AUTOSAR XML (schema 4-0-3)
package /ComponentTypes
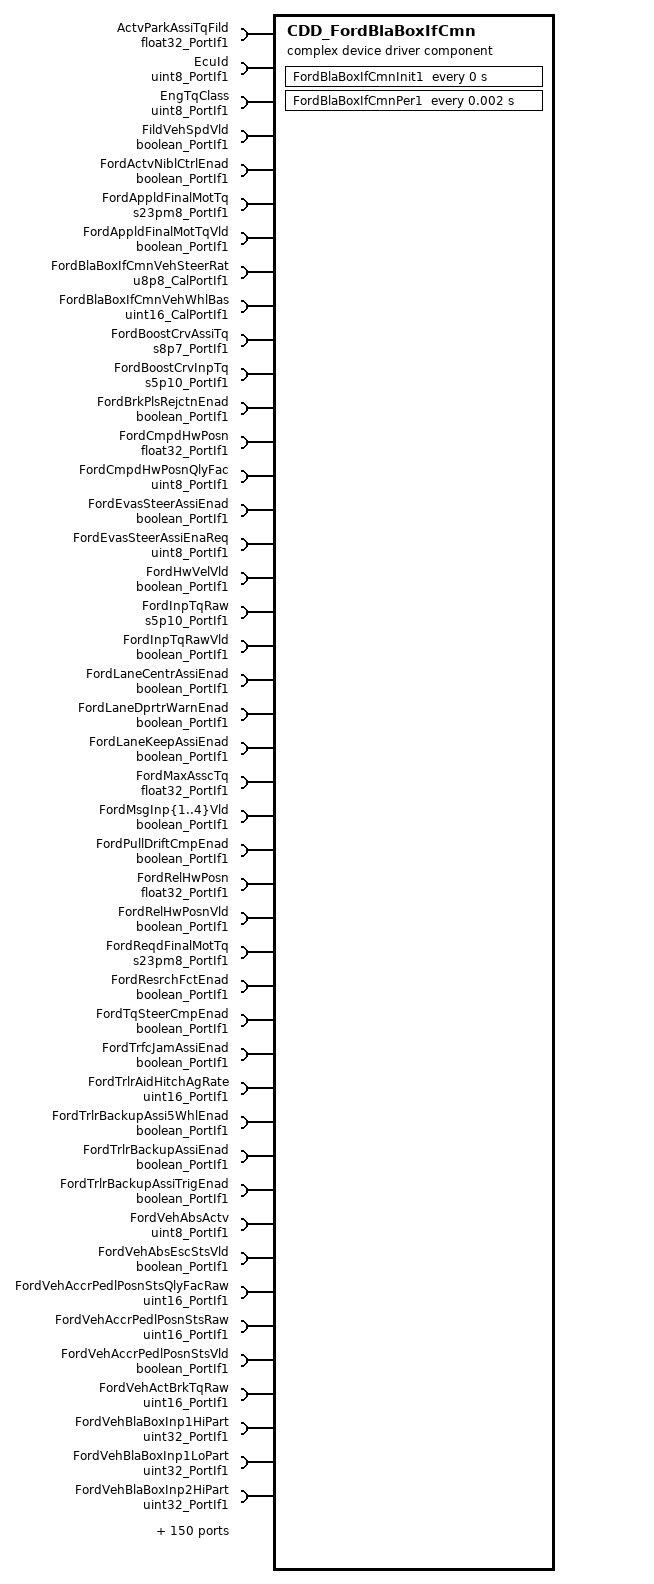
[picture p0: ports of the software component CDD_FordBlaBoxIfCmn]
  complex device driver sw component type CDD_FordBlaBoxIfCmn
    200 x require port:
      ActvParkAssiTqFild: nonqueued-receiver-com-spec{data-element=Val, filter=data-filter-type=ALWAYS, init-value=0}, required-interface=float32_PortIf1
      EcuId: nonqueued-receiver-com-spec{data-element=Val, filter=data-filter-type=ALWAYS, init-value=0}, required-interface=uint8_PortIf1
      EngTqClass: nonqueued-receiver-com-spec{data-element=Val, filter=data-filter-type=ALWAYS, init-value=2}, required-interface=uint8_PortIf1
      FildVehSpdVld: nonqueued-receiver-com-spec{data-element=Logl, filter=data-filter-type=ALWAYS, init-value=0}, required-interface=boolean_PortIf1
      FordActvNiblCtrlEnad: nonqueued-receiver-com-spec{data-element=Logl, filter=data-filter-type=ALWAYS, init-value=0}, required-interface=boolean_PortIf1
      FordAppldFinalMotTq: nonqueued-receiver-com-spec{data-element=Val, filter=data-filter-type=ALWAYS, init-value=0}, required-interface=s23pm8_PortIf1
      FordAppldFinalMotTqVld: nonqueued-receiver-com-spec{data-element=Logl, filter=data-filter-type=ALWAYS, init-value=0}, required-interface=boolean_PortIf1
      FordBlaBoxIfCmnVehSteerRat: parameter-require-com-spec{init-value=0, parameter=Val}, required-interface=u8p8_CalPortIf1
      FordBlaBoxIfCmnVehWhlBas: parameter-require-com-spec{init-value=3099, parameter=Val}, required-interface=uint16_CalPortIf1
      FordBoostCrvAssiTq: nonqueued-receiver-com-spec{data-element=Val, filter=data-filter-type=ALWAYS, init-value=0}, required-interface=s8p7_PortIf1
      FordBoostCrvInpTq: nonqueued-receiver-com-spec{data-element=Val, filter=data-filter-type=ALWAYS, init-value=0}, required-interface=s5p10_PortIf1
      FordBrkPlsRejctnEnad: nonqueued-receiver-com-spec{data-element=Logl, filter=data-filter-type=ALWAYS, init-value=0}, required-interface=boolean_PortIf1
      FordCmpdHwPosn: nonqueued-receiver-com-spec{data-element=Val, filter=data-filter-type=ALWAYS, init-value=0}, required-interface=float32_PortIf1
      FordCmpdHwPosnQlyFac: nonqueued-receiver-com-spec{data-element=Val, filter=data-filter-type=ALWAYS, init-value=1}, required-interface=uint8_PortIf1
      FordEvasSteerAssiEnad: nonqueued-receiver-com-spec{data-element=Logl, filter=data-filter-type=ALWAYS, init-value=0}, required-interface=boolean_PortIf1
      FordEvasSteerAssiEnaReq: nonqueued-receiver-com-spec{data-element=Val, filter=data-filter-type=ALWAYS, init-value=0}, required-interface=uint8_PortIf1
      FordHwVelVld: nonqueued-receiver-com-spec{data-element=Logl, filter=data-filter-type=ALWAYS, init-value=0}, required-interface=boolean_PortIf1
      FordInpTqRaw: nonqueued-receiver-com-spec{data-element=Val, filter=data-filter-type=ALWAYS, init-value=0}, required-interface=s5p10_PortIf1
      FordInpTqRawVld: nonqueued-receiver-com-spec{data-element=Logl, filter=data-filter-type=ALWAYS, init-value=0}, required-interface=boolean_PortIf1
      FordLaneCentrAssiEnad: nonqueued-receiver-com-spec{data-element=Logl, filter=data-filter-type=ALWAYS, init-value=0}, required-interface=boolean_PortIf1
      FordLaneDprtrWarnEnad: nonqueued-receiver-com-spec{data-element=Logl, filter=data-filter-type=ALWAYS, init-value=0}, required-interface=boolean_PortIf1
      FordLaneKeepAssiEnad: nonqueued-receiver-com-spec{data-element=Logl, filter=data-filter-type=ALWAYS, init-value=0}, required-interface=boolean_PortIf1
      FordMaxAsscTq: nonqueued-receiver-com-spec{data-element=Val, filter=data-filter-type=ALWAYS, init-value=0}, required-interface=float32_PortIf1
      FordMsgInp{1..4}Vld: nonqueued-receiver-com-spec{data-element=Logl, filter=data-filter-type=ALWAYS, init-value=0}, required-interface=boolean_PortIf1
      FordPullDriftCmpEnad: nonqueued-receiver-com-spec{data-element=Logl, filter=data-filter-type=ALWAYS, init-value=0}, required-interface=boolean_PortIf1
      FordRelHwPosn: nonqueued-receiver-com-spec{data-element=Val, filter=data-filter-type=ALWAYS, init-value=0}, required-interface=float32_PortIf1
      FordRelHwPosnVld: nonqueued-receiver-com-spec{data-element=Logl, filter=data-filter-type=ALWAYS, init-value=0}, required-interface=boolean_PortIf1
      FordReqdFinalMotTq: nonqueued-receiver-com-spec{data-element=Val, filter=data-filter-type=ALWAYS, init-value=0}, required-interface=s23pm8_PortIf1
      FordResrchFctEnad: nonqueued-receiver-com-spec{data-element=Logl, filter=data-filter-type=ALWAYS, init-value=0}, required-interface=boolean_PortIf1
      FordTqSteerCmpEnad: nonqueued-receiver-com-spec{data-element=Logl, filter=data-filter-type=ALWAYS, init-value=0}, required-interface=boolean_PortIf1
      FordTrfcJamAssiEnad: nonqueued-receiver-com-spec{data-element=Logl, filter=data-filter-type=ALWAYS, init-value=0}, required-interface=boolean_PortIf1
      FordTrlrAidHitchAgRate: nonqueued-receiver-com-spec{data-element=Val, filter=data-filter-type=ALWAYS, init-value=0}, required-interface=uint16_PortIf1
      FordTrlrBackupAssi5WhlEnad: nonqueued-receiver-com-spec{data-element=Logl, filter=data-filter-type=ALWAYS, init-value=0}, required-interface=boolean_PortIf1
      FordTrlrBackupAssiEnad: nonqueued-receiver-com-spec{data-element=Logl, filter=data-filter-type=ALWAYS, init-value=0}, required-interface=boolean_PortIf1
      FordTrlrBackupAssiTrigEnad: nonqueued-receiver-com-spec{data-element=Logl, filter=data-filter-type=ALWAYS, init-value=0}, required-interface=boolean_PortIf1
      FordVehAbsActv: nonqueued-receiver-com-spec{data-element=Val, filter=data-filter-type=ALWAYS, init-value=0}, required-interface=uint8_PortIf1
      FordVehAbsEscStsVld: nonqueued-receiver-com-spec{data-element=Logl, filter=data-filter-type=ALWAYS, init-value=0}, required-interface=boolean_PortIf1
      FordVehAccrPedlPosnStsQlyFacRaw: nonqueued-receiver-com-spec{data-element=Val, filter=data-filter-type=ALWAYS, init-value=0}, required-interface=uint16_PortIf1
      FordVehAccrPedlPosnStsRaw: nonqueued-receiver-com-spec{data-element=Val, filter=data-filter-type=ALWAYS, init-value=0}, required-interface=uint16_PortIf1
      FordVehAccrPedlPosnStsVld: nonqueued-receiver-com-spec{data-element=Logl, filter=data-filter-type=ALWAYS, init-value=0}, required-interface=boolean_PortIf1
      FordVehActBrkTqRaw: nonqueued-receiver-com-spec{data-element=Val, filter=data-filter-type=ALWAYS, init-value=0}, required-interface=uint16_PortIf1
      FordVehBlaBoxInp1HiPart: nonqueued-receiver-com-spec{data-element=Val, filter=data-filter-type=ALWAYS, init-value=0}, required-interface=uint32_PortIf1
      FordVehBlaBoxInp1LoPart: nonqueued-receiver-com-spec{data-element=Val, filter=data-filter-type=ALWAYS, init-value=0}, required-interface=uint32_PortIf1
      FordVehBlaBoxInp2HiPart: nonqueued-receiver-com-spec{data-element=Val, filter=data-filter-type=ALWAYS, init-value=0}, required-interface=uint32_PortIf1
      FordVehBlaBoxInp2LoPart: nonqueued-receiver-com-spec{data-element=Val, filter=data-filter-type=ALWAYS, init-value=0}, required-interface=uint32_PortIf1
      FordVehBlaBoxInp3HiPart: nonqueued-receiver-com-spec{data-element=Val, filter=data-filter-type=ALWAYS, init-value=0}, required-interface=uint32_PortIf1
      FordVehBlaBoxInp3LoPart: nonqueued-receiver-com-spec{data-element=Val, filter=data-filter-type=ALWAYS, init-value=0}, required-interface=uint32_PortIf1
      FordVehBlaBoxInp4HiPart: nonqueued-receiver-com-spec{data-element=Val, filter=data-filter-type=ALWAYS, init-value=0}, required-interface=uint32_PortIf1
      FordVehBlaBoxInp4LoPart: nonqueued-receiver-com-spec{data-element=Val, filter=data-filter-type=ALWAYS, init-value=0}, required-interface=uint32_PortIf1
      FordVehBrkPedlAppld: nonqueued-receiver-com-spec{data-element=Val, filter=data-filter-type=ALWAYS, init-value=0}, required-interface=uint8_PortIf1
      FordVehBrkPedlAppldQlyFac: nonqueued-receiver-com-spec{data-element=Val, filter=data-filter-type=ALWAYS, init-value=0}, required-interface=uint8_PortIf1
      FordVehBrkPedlVld: nonqueued-receiver-com-spec{data-element=Logl, filter=data-filter-type=ALWAYS, init-value=0}, required-interface=boolean_PortIf1
      FordVehBrkTqVld: nonqueued-receiver-com-spec{data-element=Logl, filter=data-filter-type=ALWAYS, init-value=0}, required-interface=boolean_PortIf1
      FordVehCllsnMtgtnByBrkgDenied: nonqueued-receiver-com-spec{data-element=Val, filter=data-filter-type=ALWAYS, init-value=0}, required-interface=uint8_PortIf1
      FordVehCllsnMtgtnByBrkgDisad: nonqueued-receiver-com-spec{data-element=Val, filter=data-filter-type=ALWAYS, init-value=0}, required-interface=uint8_PortIf1
      FordVehCllsnMtgtnByBrkgLatDstRaw: nonqueued-receiver-com-spec{data-element=Val, filter=data-filter-type=ALWAYS, init-value=0}, required-interface=uint16_PortIf1
      FordVehCllsnMtgtnByBrkgLgtDstRaw: nonqueued-receiver-com-spec{data-element=Val, filter=data-filter-type=ALWAYS, init-value=0}, required-interface=uint16_PortIf1
      FordVehCllsnMtgtnByBrkgObjDataConfLvlRaw: nonqueued-receiver-com-spec{data-element=Val, filter=data-filter-type=ALWAYS, init-value=0}, required-interface=uint8_PortIf1
      FordVehCllsnMtgtnByBrkgObjTypClassnRaw: nonqueued-receiver-com-spec{data-element=Val, filter=data-filter-type=ALWAYS, init-value=0}, required-interface=uint8_PortIf1
      FordVehCllsnMtgtnByBrkgRelLatVelRaw: nonqueued-receiver-com-spec{data-element=Val, filter=data-filter-type=ALWAYS, init-value=0}, required-interface=uint16_PortIf1
      FordVehCllsnMtgtnByBrkgRelLgtVelRaw: nonqueued-receiver-com-spec{data-element=Val, filter=data-filter-type=ALWAYS, init-value=0}, required-interface=uint16_PortIf1
      FordVehCllsnMtgtnByBrkgTiToCllsnRaw: nonqueued-receiver-com-spec{data-element=Val, filter=data-filter-type=ALWAYS, init-value=0}, required-interface=uint8_PortIf1
      FordVehEngSpdRaw: nonqueued-receiver-com-spec{data-element=Val, filter=data-filter-type=ALWAYS, init-value=0}, required-interface=uint16_PortIf1
      FordVehEngSpdVld: nonqueued-receiver-com-spec{data-element=Logl, filter=data-filter-type=ALWAYS, init-value=0}, required-interface=boolean_PortIf1
      FordVehEscActv: nonqueued-receiver-com-spec{data-element=Val, filter=data-filter-type=ALWAYS, init-value=0}, required-interface=uint8_PortIf1
      FordVehEvasSteerAssiImgProcrModlAVld: nonqueued-receiver-com-spec{data-element=Logl, filter=data-filter-type=ALWAYS, init-value=0}, required-interface=boolean_PortIf1
      FordVehEvasSteerAssiReq: nonqueued-receiver-com-spec{data-element=Val, filter=data-filter-type=ALWAYS, init-value=0}, required-interface=uint8_PortIf1
      FordVehEvasSteerAssiReqVld: nonqueued-receiver-com-spec{data-element=Logl, filter=data-filter-type=ALWAYS, init-value=0}, required-interface=boolean_PortIf1
      FordVehFrntLeWhlCntrDirVld: nonqueued-receiver-com-spec{data-element=Logl, filter=data-filter-type=ALWAYS, init-value=0}, required-interface=boolean_PortIf1
      FordVehFrntLeWhlDirRaw: nonqueued-receiver-com-spec{data-element=Val, filter=data-filter-type=ALWAYS, init-value=0}, required-interface=uint8_PortIf1
      FordVehFrntLeWhlRollgCntr: nonqueued-receiver-com-spec{data-element=Val, filter=data-filter-type=ALWAYS, init-value=0}, required-interface=uint8_PortIf1
      FordVehFrntLeWhlSpdRaw: nonqueued-receiver-com-spec{data-element=Val, filter=data-filter-type=ALWAYS, init-value=0}, required-interface=uint16_PortIf1
      FordVehFrntLeWhlSpdVld: nonqueued-receiver-com-spec{data-element=Logl, filter=data-filter-type=ALWAYS, init-value=0}, required-interface=boolean_PortIf1
      FordVehFrntRiWhlCntrDirVld: nonqueued-receiver-com-spec{data-element=Logl, filter=data-filter-type=ALWAYS, init-value=0}, required-interface=boolean_PortIf1
      FordVehFrntRiWhlDirRaw: nonqueued-receiver-com-spec{data-element=Val, filter=data-filter-type=ALWAYS, init-value=0}, required-interface=uint8_PortIf1
      FordVehFrntRiWhlRollgCntr: nonqueued-receiver-com-spec{data-element=Val, filter=data-filter-type=ALWAYS, init-value=0}, required-interface=uint8_PortIf1
      FordVehFrntRiWhlSpdRaw: nonqueued-receiver-com-spec{data-element=Val, filter=data-filter-type=ALWAYS, init-value=0}, required-interface=uint16_PortIf1
      FordVehFrntRiWhlSpdVld: nonqueued-receiver-com-spec{data-element=Logl, filter=data-filter-type=ALWAYS, init-value=0}, required-interface=boolean_PortIf1
      FordVehGearLvrPosn: nonqueued-receiver-com-spec{data-element=Val, filter=data-filter-type=ALWAYS, init-value=0}, required-interface=uint8_PortIf1
      FordVehGearLvrPosnVldInt: nonqueued-receiver-com-spec{data-element=Logl, filter=data-filter-type=ALWAYS, init-value=0}, required-interface=boolean_PortIf1
      FordVehGearPosnRaw: nonqueued-receiver-com-spec{data-element=Val, filter=data-filter-type=ALWAYS, init-value=0}, required-interface=uint8_PortIf1
      FordVehGearRvsStsRaw: nonqueued-receiver-com-spec{data-element=Val, filter=data-filter-type=ALWAYS, init-value=0}, required-interface=uint8_PortIf1
      FordVehGearRvsStsVld: nonqueued-receiver-com-spec{data-element=Logl, filter=data-filter-type=ALWAYS, init-value=0}, required-interface=boolean_PortIf1
      FordVehIgnSts: nonqueued-receiver-com-spec{data-element=Val, filter=data-filter-type=ALWAYS, init-value=0}, required-interface=uint8_PortIf1
      FordVehIgnStsVld: nonqueued-receiver-com-spec{data-element=Logl, filter=data-filter-type=ALWAYS, init-value=0}, required-interface=boolean_PortIf1
      FordVehLaneAssiImgProcgModlAVld: nonqueued-receiver-com-spec{data-element=Logl, filter=data-filter-type=ALWAYS, init-value=0}, required-interface=boolean_PortIf1
      FordVehLaneDetnWarnInten: nonqueued-receiver-com-spec{data-element=Val, filter=data-filter-type=ALWAYS, init-value=0}, required-interface=uint8_PortIf1
      FordVehLaneDetnWarnSts: nonqueued-receiver-com-spec{data-element=Val, filter=data-filter-type=ALWAYS, init-value=0}, required-interface=uint8_PortIf1
      FordVehLaneKeepSysCrvtRaw: nonqueued-receiver-com-spec{data-element=Val, filter=data-filter-type=ALWAYS, init-value=0}, required-interface=uint16_PortIf1
      FordVehLaneKeepSysRampTyp: nonqueued-receiver-com-spec{data-element=Val, filter=data-filter-type=ALWAYS, init-value=0}, required-interface=uint8_PortIf1
      FordVehLaneKeepSysReqdAgRaw: nonqueued-receiver-com-spec{data-element=Val, filter=data-filter-type=ALWAYS, init-value=0}, required-interface=uint16_PortIf1
      FordVehLaneKeepSysSts: nonqueued-receiver-com-spec{data-element=Val, filter=data-filter-type=ALWAYS, init-value=0}, required-interface=uint8_PortIf1
      FordVehLatACmpdRaw: nonqueued-receiver-com-spec{data-element=Val, filter=data-filter-type=ALWAYS, init-value=0}, required-interface=uint16_PortIf1
      FordVehLatACmpdVld: nonqueued-receiver-com-spec{data-element=Logl, filter=data-filter-type=ALWAYS, init-value=0}, required-interface=boolean_PortIf1
      FordVehLatCtrlCrvtRateRaw: nonqueued-receiver-com-spec{data-element=Val, filter=data-filter-type=ALWAYS, init-value=0}, required-interface=uint16_PortIf1
      FordVehLatCtrlCrvtRaw: nonqueued-receiver-com-spec{data-element=Val, filter=data-filter-type=ALWAYS, init-value=0}, required-interface=uint16_PortIf1
      FordVehLatCtrlHandsOffDetnTqStimlsReq: nonqueued-receiver-com-spec{data-element=Val, filter=data-filter-type=ALWAYS, init-value=0}, required-interface=uint8_PortIf1
      FordVehLatCtrlImgProcrModlAVld: nonqueued-receiver-com-spec{data-element=Logl, filter=data-filter-type=ALWAYS, init-value=0}, required-interface=boolean_PortIf1
      FordVehLatCtrlPahOffsRaw: nonqueued-receiver-com-spec{data-element=Val, filter=data-filter-type=ALWAYS, init-value=0}, required-interface=uint16_PortIf1
      FordVehLatCtrlPahRaw: nonqueued-receiver-com-spec{data-element=Val, filter=data-filter-type=ALWAYS, init-value=0}, required-interface=uint16_PortIf1
      FordVehLatCtrlPrcsn: nonqueued-receiver-com-spec{data-element=Val, filter=data-filter-type=ALWAYS, init-value=0}, required-interface=uint8_PortIf1
      FordVehLatCtrlRampTyp: nonqueued-receiver-com-spec{data-element=Val, filter=data-filter-type=ALWAYS, init-value=0}, required-interface=uint8_PortIf1
      FordVehLatCtrlReq: nonqueued-receiver-com-spec{data-element=Val, filter=data-filter-type=ALWAYS, init-value=0}, required-interface=uint8_PortIf1
      FordVehLatCtrlRingMax: nonqueued-receiver-com-spec{data-element=Val, filter=data-filter-type=ALWAYS, init-value=0}, required-interface=uint8_PortIf1
      FordVehLgtACmpdRaw: nonqueued-receiver-com-spec{data-element=Val, filter=data-filter-type=ALWAYS, init-value=0}, required-interface=uint16_PortIf1
      FordVehLgtACmpdVld: nonqueued-receiver-com-spec{data-element=Logl, filter=data-filter-type=ALWAYS, init-value=0}, required-interface=boolean_PortIf1
      FordVehLoSpdMtnCtrlBrkSprtStsRaw: nonqueued-receiver-com-spec{data-element=Val, filter=data-filter-type=ALWAYS, init-value=0}, required-interface=uint8_PortIf1
      FordVehLoSpdMtnCtrlBrkSprtVld: nonqueued-receiver-com-spec{data-element=Logl, filter=data-filter-type=ALWAYS, init-value=0}, required-interface=boolean_PortIf1
      FordVehParkAidModlStsVld: nonqueued-receiver-com-spec{data-element=Logl, filter=data-filter-type=ALWAYS, init-value=0}, required-interface=boolean_PortIf1
      FordVehParkAidModlSysSt: nonqueued-receiver-com-spec{data-element=Val, filter=data-filter-type=ALWAYS, init-value=0}, required-interface=uint8_PortIf1
      FordVehPrpnWhlTqRaw: nonqueued-receiver-com-spec{data-element=Val, filter=data-filter-type=ALWAYS, init-value=0}, required-interface=uint16_PortIf1
      FordVehPrpnWhlTqVld: nonqueued-receiver-com-spec{data-element=Logl, filter=data-filter-type=ALWAYS, init-value=0}, required-interface=boolean_PortIf1
      FordVehReLeWhlCntrDirVld: nonqueued-receiver-com-spec{data-element=Logl, filter=data-filter-type=ALWAYS, init-value=0}, required-interface=boolean_PortIf1
      FordVehReLeWhlDirRaw: nonqueued-receiver-com-spec{data-element=Val, filter=data-filter-type=ALWAYS, init-value=0}, required-interface=uint8_PortIf1
      FordVehReLeWhlRollgCntr: nonqueued-receiver-com-spec{data-element=Val, filter=data-filter-type=ALWAYS, init-value=0}, required-interface=uint8_PortIf1
      FordVehReLeWhlSpdRaw: nonqueued-receiver-com-spec{data-element=Val, filter=data-filter-type=ALWAYS, init-value=0}, required-interface=uint16_PortIf1
      FordVehReLeWhlSpdVld: nonqueued-receiver-com-spec{data-element=Logl, filter=data-filter-type=ALWAYS, init-value=0}, required-interface=boolean_PortIf1
      FordVehReRiWhlCntrDirVld: nonqueued-receiver-com-spec{data-element=Logl, filter=data-filter-type=ALWAYS, init-value=0}, required-interface=boolean_PortIf1
      FordVehReRiWhlDirRaw: nonqueued-receiver-com-spec{data-element=Val, filter=data-filter-type=ALWAYS, init-value=0}, required-interface=uint8_PortIf1
      FordVehReRiWhlRollgCntr: nonqueued-receiver-com-spec{data-element=Val, filter=data-filter-type=ALWAYS, init-value=0}, required-interface=uint8_PortIf1
      FordVehReRiWhlSpdRaw: nonqueued-receiver-com-spec{data-element=Val, filter=data-filter-type=ALWAYS, init-value=0}, required-interface=uint16_PortIf1
      FordVehReRiWhlSpdVld: nonqueued-receiver-com-spec{data-element=Logl, filter=data-filter-type=ALWAYS, init-value=0}, required-interface=boolean_PortIf1
      FordVehSelDrvModChassisVld: nonqueued-receiver-com-spec{data-element=Logl, filter=data-filter-type=ALWAYS, init-value=0}, required-interface=boolean_PortIf1
      FordVehSpd: nonqueued-receiver-com-spec{data-element=Val, filter=data-filter-type=ALWAYS, init-value=0}, required-interface=float32_PortIf1
      FordVehSpdBrkModlRaw: nonqueued-receiver-com-spec{data-element=Val, filter=data-filter-type=ALWAYS, init-value=0}, required-interface=uint16_PortIf1
      FordVehSpdOverGndRaw: nonqueued-receiver-com-spec{data-element=Val, filter=data-filter-type=ALWAYS, init-value=0}, required-interface=uint16_PortIf1
      FordVehSpdOverGndVld: nonqueued-receiver-com-spec{data-element=Logl, filter=data-filter-type=ALWAYS, init-value=0}, required-interface=boolean_PortIf1
      FordVehSteerPinionAgOffsRaw: nonqueued-receiver-com-spec{data-element=Val, filter=data-filter-type=ALWAYS, init-value=0}, required-interface=uint16_PortIf1
      FordVehSteerPinionAgOffsVld: nonqueued-receiver-com-spec{data-element=Logl, filter=data-filter-type=ALWAYS, init-value=0}, required-interface=boolean_PortIf1
      FordVehSteerPinionOffsStsRaw: nonqueued-receiver-com-spec{data-element=Val, filter=data-filter-type=ALWAYS, init-value=0}, required-interface=uint8_PortIf1
      FordVehTireCircum: nonqueued-receiver-com-spec{data-element=Val, filter=data-filter-type=ALWAYS, init-value=0}, required-interface=float32_PortIf1
      FordVehTrlrAgOffsDirRaw: nonqueued-receiver-com-spec{data-element=Val, filter=data-filter-type=ALWAYS, init-value=0}, required-interface=uint8_PortIf1
      FordVehTrlrAidAcqSts: nonqueued-receiver-com-spec{data-element=Val, filter=data-filter-type=ALWAYS, init-value=0}, required-interface=uint8_PortIf1
      FordVehTrlrAidAvlRaw: nonqueued-receiver-com-spec{data-element=Val, filter=data-filter-type=ALWAYS, init-value=0}, required-interface=uint8_PortIf1
      FordVehTrlrAidCnclReq: nonqueued-receiver-com-spec{data-element=Val, filter=data-filter-type=ALWAYS, init-value=0}, required-interface=uint8_PortIf1
      FordVehTrlrAidCnclReqVld: nonqueued-receiver-com-spec{data-element=Logl, filter=data-filter-type=ALWAYS, init-value=0}, required-interface=boolean_PortIf1
      FordVehTrlrAidHitchAg: nonqueued-receiver-com-spec{data-element=Val, filter=data-filter-type=ALWAYS, init-value=0}, required-interface=uint16_PortIf1
      FordVehTrlrAidIdnNrRaw: nonqueued-receiver-com-spec{data-element=Val, filter=data-filter-type=ALWAYS, init-value=0}, required-interface=uint8_PortIf1
      FordVehTrlrAidIdnVal: nonqueued-receiver-com-spec{data-element=Val, filter=data-filter-type=ALWAYS, init-value=0}, required-interface=uint8_PortIf1
      FordVehTrlrAidKnobBtn: nonqueued-receiver-com-spec{data-element=Val, filter=data-filter-type=ALWAYS, init-value=0}, required-interface=uint8_PortIf1
      FordVehTrlrAidKnobPosn: nonqueued-receiver-com-spec{data-element=Val, filter=data-filter-type=ALWAYS, init-value=0}, required-interface=uint16_PortIf1
      FordVehTrlrAidKnobPosnVld: nonqueued-receiver-com-spec{data-element=Logl, filter=data-filter-type=ALWAYS, init-value=0}, required-interface=boolean_PortIf1
      FordVehTrlrAidKnobStsVld: nonqueued-receiver-com-spec{data-element=Logl, filter=data-filter-type=ALWAYS, init-value=0}, required-interface=boolean_PortIf1
      FordVehTrlrAidModReq: nonqueued-receiver-com-spec{data-element=Val, filter=data-filter-type=ALWAYS, init-value=0}, required-interface=uint8_PortIf1
      FordVehTrlrAidModReqVld: nonqueued-receiver-com-spec{data-element=Logl, filter=data-filter-type=ALWAYS, init-value=0}, required-interface=boolean_PortIf1
      FordVehTrlrAidSetUpRaw: nonqueued-receiver-com-spec{data-element=Val, filter=data-filter-type=ALWAYS, init-value=0}, required-interface=uint8_PortIf1
      FordVehTrlrAidTrakgSt: nonqueued-receiver-com-spec{data-element=Val, filter=data-filter-type=ALWAYS, init-value=0}, required-interface=uint8_PortIf1
      FordVehTrlrAidTrakgStVld: nonqueued-receiver-com-spec{data-element=Logl, filter=data-filter-type=ALWAYS, init-value=0}, required-interface=boolean_PortIf1
      FordVehTrlrAidTrlrRvsGuidcSts: nonqueued-receiver-com-spec{data-element=Val, filter=data-filter-type=ALWAYS, init-value=0}, required-interface=uint8_PortIf1
      FordVehTrlrAxleToBmpRaw: nonqueued-receiver-com-spec{data-element=Val, filter=data-filter-type=ALWAYS, init-value=0}, required-interface=uint16_PortIf1
      FordVehTrlrBackupAssiAvlVld: nonqueued-receiver-com-spec{data-element=Logl, filter=data-filter-type=ALWAYS, init-value=0}, required-interface=boolean_PortIf1
      FordVehTrlrBackupAssiMeasVld: nonqueued-receiver-com-spec{data-element=Logl, filter=data-filter-type=ALWAYS, init-value=0}, required-interface=boolean_PortIf1
      FordVehTrlrBallToAxle: nonqueued-receiver-com-spec{data-element=Val, filter=data-filter-type=ALWAYS, init-value=0}, required-interface=uint8_PortIf1
      FordVehTrlrBrkCnctnStsRaw: nonqueued-receiver-com-spec{data-element=Val, filter=data-filter-type=ALWAYS, init-value=0}, required-interface=uint8_PortIf1
      FordVehTrlrEnaReqRaw: nonqueued-receiver-com-spec{data-element=Val, filter=data-filter-type=ALWAYS, init-value=0}, required-interface=uint8_PortIf1
      FordVehTrlrHitchAgRateRaw: nonqueued-receiver-com-spec{data-element=Val, filter=data-filter-type=ALWAYS, init-value=0}, required-interface=uint16_PortIf1
      FordVehTrlrHitchAgVld: nonqueued-receiver-com-spec{data-element=Logl, filter=data-filter-type=ALWAYS, init-value=0}, required-interface=boolean_PortIf1
      FordVehTrlrHitchRateVld: nonqueued-receiver-com-spec{data-element=Logl, filter=data-filter-type=ALWAYS, init-value=0}, required-interface=boolean_PortIf1
      FordVehTrlrHitchYawAgRaw: nonqueued-receiver-com-spec{data-element=Val, filter=data-filter-type=ALWAYS, init-value=0}, required-interface=uint16_PortIf1
      FordVehTrlrHitchYawSts: nonqueued-receiver-com-spec{data-element=Val, filter=data-filter-type=ALWAYS, init-value=0}, required-interface=uint8_PortIf1
      FordVehTrlrIdnTypRaw: nonqueued-receiver-com-spec{data-element=Val, filter=data-filter-type=ALWAYS, init-value=0}, required-interface=uint16_PortIf1
      FordVehTrlrLampCnctnStsRaw: nonqueued-receiver-com-spec{data-element=Val, filter=data-filter-type=ALWAYS, init-value=0}, required-interface=uint8_PortIf1
      FordVehTrlrRvsCnclReqRaw: nonqueued-receiver-com-spec{data-element=Val, filter=data-filter-type=ALWAYS, init-value=0}, required-interface=uint8_PortIf1
      FordVehTrlrRvsEnaRaw: nonqueued-receiver-com-spec{data-element=Val, filter=data-filter-type=ALWAYS, init-value=0}, required-interface=uint8_PortIf1
      FordVehTrlrRvsMsgTxtReqRaw: nonqueued-receiver-com-spec{data-element=Val, filter=data-filter-type=ALWAYS, init-value=0}, required-interface=uint8_PortIf1
      FordVehTrlrTarVld: nonqueued-receiver-com-spec{data-element=Logl, filter=data-filter-type=ALWAYS, init-value=0}, required-interface=boolean_PortIf1
      FordVehTrlrYawRateQlyFac: nonqueued-receiver-com-spec{data-element=Val, filter=data-filter-type=ALWAYS, init-value=0}, required-interface=uint8_PortIf1
      FordVehTrlrYawRateRaw: nonqueued-receiver-com-spec{data-element=Val, filter=data-filter-type=ALWAYS, init-value=0}, required-interface=uint16_PortIf1
      FordVehTrsmDesGearRaw: nonqueued-receiver-com-spec{data-element=Val, filter=data-filter-type=ALWAYS, init-value=0}, required-interface=uint8_PortIf1
      FordVehTurnSigSwtStsRaw: nonqueued-receiver-com-spec{data-element=Val, filter=data-filter-type=ALWAYS, init-value=0}, required-interface=uint8_PortIf1
      FordVehTurnSigVld: nonqueued-receiver-com-spec{data-element=Logl, filter=data-filter-type=ALWAYS, init-value=0}, required-interface=boolean_PortIf1
      FordVehVertACmpdRaw: nonqueued-receiver-com-spec{data-element=Val, filter=data-filter-type=ALWAYS, init-value=0}, required-interface=uint16_PortIf1
      FordVehYawRateCmpdRaw: nonqueued-receiver-com-spec{data-element=Val, filter=data-filter-type=ALWAYS, init-value=0}, required-interface=uint16_PortIf1
      FordVehYawRateRaw: nonqueued-receiver-com-spec{data-element=Ford_VehYaw_W_Actl, filter=data-filter-type=ALWAYS}, required-interface=Ford_VehYaw_W_Actl
      FordVehYawRateRawVld: nonqueued-receiver-com-spec{data-element=Logl, filter=data-filter-type=ALWAYS, init-value=0}, required-interface=boolean_PortIf1
      FordVehYawRateVld: nonqueued-receiver-com-spec{data-element=Logl, filter=data-filter-type=ALWAYS, init-value=0}, required-interface=boolean_PortIf1
      FordVehYawStabyRaw: nonqueued-receiver-com-spec{data-element=Val, filter=data-filter-type=ALWAYS, init-value=0}, required-interface=uint16_PortIf1
      FordVehYawStabyVld: nonqueued-receiver-com-spec{data-element=Logl, filter=data-filter-type=ALWAYS, init-value=0}, required-interface=boolean_PortIf1
      FordYawRateSnsrIdHi: nonqueued-receiver-com-spec{data-element=Val, filter=data-filter-type=ALWAYS, init-value=0}, required-interface=uint32_PortIf1
      FordYawRateSnsrIdLo: nonqueued-receiver-com-spec{data-element=Val, filter=data-filter-type=ALWAYS, init-value=0}, required-interface=uint32_PortIf1
      HwVel: nonqueued-receiver-com-spec{data-element=Val, filter=data-filter-type=ALWAYS, init-value=0}, required-interface=float32_PortIf1
      IntAgCtrlSt: nonqueued-receiver-com-spec{data-element=Val, filter=data-filter-type=ALWAYS, init-value=0}, required-interface=uint8_PortIf1
      RackToPinionRat: nonqueued-receiver-com-spec{data-element=Val, filter=data-filter-type=ALWAYS, init-value=0}, required-interface=u8p8_PortIf1
      SelnDrvgModSteerModReq: nonqueued-receiver-com-spec{data-element=Val, filter=data-filter-type=ALWAYS, init-value=0}, required-interface=uint8_PortIf1
      SemiAutParlParkAgCtrlSts1: nonqueued-receiver-com-spec{data-element=Val, filter=data-filter-type=ALWAYS, init-value=0}, required-interface=uint8_PortIf1
      SemiAutParlParkAgCtrlSts{2..5}: nonqueued-receiver-com-spec{data-element=Logl, filter=data-filter-type=ALWAYS, init-value=0}, required-interface=boolean_PortIf1
      TrlrBackupAssiEnaVld: nonqueued-receiver-com-spec{data-element=Logl, filter=data-filter-type=ALWAYS, init-value=0}, required-interface=boolean_PortIf1
      TrlrBackupAssiRvsVld: nonqueued-receiver-com-spec{data-element=Logl, filter=data-filter-type=ALWAYS, init-value=0}, required-interface=boolean_PortIf1
      TrlrBackupAssiYawRateVld: nonqueued-receiver-com-spec{data-element=Logl, filter=data-filter-type=ALWAYS, init-value=0}, required-interface=boolean_PortIf1
      VehSpd: nonqueued-receiver-com-spec{data-element=Val, filter=data-filter-type=ALWAYS, init-value=0}, required-interface=float32_PortIf1
      VehSpdVld: nonqueued-receiver-com-spec{data-element=Logl, filter=data-filter-type=ALWAYS, init-value=0}, required-interface=boolean_PortIf1
      VehSteerRat: nonqueued-receiver-com-spec{data-element=Val, filter=data-filter-type=ALWAYS, init-value=0}, required-interface=u8p8_PortIf1
      VehWhlBas: nonqueued-receiver-com-spec{data-element=Val, filter=data-filter-type=ALWAYS, init-value=0}, required-interface=uint16_PortIf1
      VertAVld: nonqueued-receiver-com-spec{data-element=Logl, filter=data-filter-type=ALWAYS, init-value=0}, required-interface=boolean_PortIf1
    behavior CDD_FordBlaBoxIfCmn_InternalBehavior
      timing event FordBlaBoxIfCmnInit1_InitEvent: start-on-event=FordBlaBoxIfCmnInit1, period=0
      timing event TMT_FordBlaBoxIfCmnPer1: start-on-event=FordBlaBoxIfCmnPer1, period=0.002
      port-api-options:
        enable-take-address=false, indirect-api=false, port=ActvParkAssiTqFild
        enable-take-address=false, indirect-api=false, port=EcuId
        enable-take-address=false, indirect-api=false, port=EngTqClass
        enable-take-address=false, indirect-api=false, port=FildVehSpdVld
        enable-take-address=false, indirect-api=false, port=FordActvNiblCtrlEnad
        enable-take-address=false, indirect-api=false, port=FordAppldFinalMotTq
        enable-take-address=false, indirect-api=false, port=FordAppldFinalMotTqVld
        enable-take-address=false, indirect-api=false, port=FordBlaBoxIfCmnVehSteerRat
        enable-take-address=false, indirect-api=false, port=FordBlaBoxIfCmnVehWhlBas
        enable-take-address=false, indirect-api=false, port=FordBoostCrvAssiTq
        enable-take-address=false, indirect-api=false, port=FordBoostCrvInpTq
        enable-take-address=false, indirect-api=false, port=FordBrkPlsRejctnEnad
        enable-take-address=false, indirect-api=false, port=FordCmpdHwPosn
        enable-take-address=false, indirect-api=false, port=FordCmpdHwPosnQlyFac
        enable-take-address=false, indirect-api=false, port=FordEvasSteerAssiEnad
        enable-take-address=false, indirect-api=false, port=FordEvasSteerAssiEnaReq
        enable-take-address=false, indirect-api=false, port=FordHwVelVld
        enable-take-address=false, indirect-api=false, port=FordInpTqRaw
        enable-take-address=false, indirect-api=false, port=FordInpTqRawVld
        enable-take-address=false, indirect-api=false, port=FordLaneCentrAssiEnad
        enable-take-address=false, indirect-api=false, port=FordLaneDprtrWarnEnad
        enable-take-address=false, indirect-api=false, port=FordLaneKeepAssiEnad
        enable-take-address=false, indirect-api=false, port=FordMaxAsscTq
        enable-take-address=false, indirect-api=false, port=FordMsgInp{1..4}Vld
        enable-take-address=false, indirect-api=false, port=FordPullDriftCmpEnad
        enable-take-address=false, indirect-api=false, port=FordRelHwPosn
        enable-take-address=false, indirect-api=false, port=FordRelHwPosnVld
        enable-take-address=false, indirect-api=false, port=FordReqdFinalMotTq
        enable-take-address=false, indirect-api=false, port=FordResrchFctEnad
        enable-take-address=false, indirect-api=false, port=FordTqSteerCmpEnad
        enable-take-address=false, indirect-api=false, port=FordTrfcJamAssiEnad
        enable-take-address=false, indirect-api=false, port=FordTrlrAidHitchAgRate
        enable-take-address=false, indirect-api=false, port=FordTrlrBackupAssi5WhlEnad
        enable-take-address=false, indirect-api=false, port=FordTrlrBackupAssiEnad
        enable-take-address=false, indirect-api=false, port=FordTrlrBackupAssiTrigEnad
        enable-take-address=false, indirect-api=false, port=FordVehAbsActv
        enable-take-address=false, indirect-api=false, port=FordVehAbsEscStsVld
        enable-take-address=false, indirect-api=false, port=FordVehAccrPedlPosnStsQlyFacRaw
        enable-take-address=false, indirect-api=false, port=FordVehAccrPedlPosnStsRaw
        enable-take-address=false, indirect-api=false, port=FordVehAccrPedlPosnStsVld
        enable-take-address=false, indirect-api=false, port=FordVehActBrkTqRaw
        enable-take-address=false, indirect-api=false, port=FordVehBlaBoxInp1HiPart
        enable-take-address=false, indirect-api=false, port=FordVehBlaBoxInp1LoPart
        enable-take-address=false, indirect-api=false, port=FordVehBlaBoxInp2HiPart
        enable-take-address=false, indirect-api=false, port=FordVehBlaBoxInp2LoPart
        enable-take-address=false, indirect-api=false, port=FordVehBlaBoxInp3HiPart
        enable-take-address=false, indirect-api=false, port=FordVehBlaBoxInp3LoPart
        enable-take-address=false, indirect-api=false, port=FordVehBlaBoxInp4HiPart
        enable-take-address=false, indirect-api=false, port=FordVehBlaBoxInp4LoPart
        enable-take-address=false, indirect-api=false, port=FordVehBrkPedlAppld
        enable-take-address=false, indirect-api=false, port=FordVehBrkPedlAppldQlyFac
        enable-take-address=false, indirect-api=false, port=FordVehBrkPedlVld
        enable-take-address=false, indirect-api=false, port=FordVehBrkTqVld
        enable-take-address=false, indirect-api=false, port=FordVehCllsnMtgtnByBrkgDenied
        enable-take-address=false, indirect-api=false, port=FordVehCllsnMtgtnByBrkgDisad
        enable-take-address=false, indirect-api=false, port=FordVehCllsnMtgtnByBrkgLatDstRaw
        enable-take-address=false, indirect-api=false, port=FordVehCllsnMtgtnByBrkgLgtDstRaw
        enable-take-address=false, indirect-api=false, port=FordVehCllsnMtgtnByBrkgObjDataConfLvlRaw
        enable-take-address=false, indirect-api=false, port=FordVehCllsnMtgtnByBrkgObjTypClassnRaw
        enable-take-address=false, indirect-api=false, port=FordVehCllsnMtgtnByBrkgRelLatVelRaw
        enable-take-address=false, indirect-api=false, port=FordVehCllsnMtgtnByBrkgRelLgtVelRaw
        enable-take-address=false, indirect-api=false, port=FordVehCllsnMtgtnByBrkgTiToCllsnRaw
        enable-take-address=false, indirect-api=false, port=FordVehEngSpdRaw
        enable-take-address=false, indirect-api=false, port=FordVehEngSpdVld
        enable-take-address=false, indirect-api=false, port=FordVehEscActv
        enable-take-address=false, indirect-api=false, port=FordVehEvasSteerAssiImgProcrModlAVld
        enable-take-address=false, indirect-api=false, port=FordVehEvasSteerAssiReq
        enable-take-address=false, indirect-api=false, port=FordVehEvasSteerAssiReqVld
        enable-take-address=false, indirect-api=false, port=FordVehFrntLeWhlCntrDirVld
        enable-take-address=false, indirect-api=false, port=FordVehFrntLeWhlDirRaw
        enable-take-address=false, indirect-api=false, port=FordVehFrntLeWhlRollgCntr
        enable-take-address=false, indirect-api=false, port=FordVehFrntLeWhlSpdRaw
        enable-take-address=false, indirect-api=false, port=FordVehFrntLeWhlSpdVld
        enable-take-address=false, indirect-api=false, port=FordVehFrntRiWhlCntrDirVld
        enable-take-address=false, indirect-api=false, port=FordVehFrntRiWhlDirRaw
        enable-take-address=false, indirect-api=false, port=FordVehFrntRiWhlRollgCntr
        enable-take-address=false, indirect-api=false, port=FordVehFrntRiWhlSpdRaw
        enable-take-address=false, indirect-api=false, port=FordVehFrntRiWhlSpdVld
        enable-take-address=false, indirect-api=false, port=FordVehGearLvrPosn
        enable-take-address=false, indirect-api=false, port=FordVehGearLvrPosnVldInt
        enable-take-address=false, indirect-api=false, port=FordVehGearPosnRaw
        enable-take-address=false, indirect-api=false, port=FordVehGearRvsStsRaw
        enable-take-address=false, indirect-api=false, port=FordVehGearRvsStsVld
        enable-take-address=false, indirect-api=false, port=FordVehIgnSts
        enable-take-address=false, indirect-api=false, port=FordVehIgnStsVld
        enable-take-address=false, indirect-api=false, port=FordVehLaneAssiImgProcgModlAVld
        enable-take-address=false, indirect-api=false, port=FordVehLaneDetnWarnInten
        enable-take-address=false, indirect-api=false, port=FordVehLaneDetnWarnSts
        enable-take-address=false, indirect-api=false, port=FordVehLaneKeepSysCrvtRaw
        enable-take-address=false, indirect-api=false, port=FordVehLaneKeepSysRampTyp
        enable-take-address=false, indirect-api=false, port=FordVehLaneKeepSysReqdAgRaw
        enable-take-address=false, indirect-api=false, port=FordVehLaneKeepSysSts
        enable-take-address=false, indirect-api=false, port=FordVehLatACmpdRaw
        enable-take-address=false, indirect-api=false, port=FordVehLatACmpdVld
        enable-take-address=false, indirect-api=false, port=FordVehLatCtrlCrvtRateRaw
        enable-take-address=false, indirect-api=false, port=FordVehLatCtrlCrvtRaw
        enable-take-address=false, indirect-api=false, port=FordVehLatCtrlHandsOffDetnTqStimlsReq
        enable-take-address=false, indirect-api=false, port=FordVehLatCtrlImgProcrModlAVld
        enable-take-address=false, indirect-api=false, port=FordVehLatCtrlPahOffsRaw
        enable-take-address=false, indirect-api=false, port=FordVehLatCtrlPahRaw
        enable-take-address=false, indirect-api=false, port=FordVehLatCtrlPrcsn
        enable-take-address=false, indirect-api=false, port=FordVehLatCtrlRampTyp
        enable-take-address=false, indirect-api=false, port=FordVehLatCtrlReq
        enable-take-address=false, indirect-api=false, port=FordVehLatCtrlRingMax
        enable-take-address=false, indirect-api=false, port=FordVehLgtACmpdRaw
        enable-take-address=false, indirect-api=false, port=FordVehLgtACmpdVld
        enable-take-address=false, indirect-api=false, port=FordVehLoSpdMtnCtrlBrkSprtStsRaw
        enable-take-address=false, indirect-api=false, port=FordVehLoSpdMtnCtrlBrkSprtVld
        enable-take-address=false, indirect-api=false, port=FordVehParkAidModlStsVld
        enable-take-address=false, indirect-api=false, port=FordVehParkAidModlSysSt
        enable-take-address=false, indirect-api=false, port=FordVehPrpnWhlTqRaw
        enable-take-address=false, indirect-api=false, port=FordVehPrpnWhlTqVld
        enable-take-address=false, indirect-api=false, port=FordVehReLeWhlCntrDirVld
        enable-take-address=false, indirect-api=false, port=FordVehReLeWhlDirRaw
        enable-take-address=false, indirect-api=false, port=FordVehReLeWhlRollgCntr
        enable-take-address=false, indirect-api=false, port=FordVehReLeWhlSpdRaw
        enable-take-address=false, indirect-api=false, port=FordVehReLeWhlSpdVld
        enable-take-address=false, indirect-api=false, port=FordVehReRiWhlCntrDirVld
        enable-take-address=false, indirect-api=false, port=FordVehReRiWhlDirRaw
        enable-take-address=false, indirect-api=false, port=FordVehReRiWhlRollgCntr
        enable-take-address=false, indirect-api=false, port=FordVehReRiWhlSpdRaw
        enable-take-address=false, indirect-api=false, port=FordVehReRiWhlSpdVld
        enable-take-address=false, indirect-api=false, port=FordVehSelDrvModChassisVld
        enable-take-address=false, indirect-api=false, port=FordVehSpd
        enable-take-address=false, indirect-api=false, port=FordVehSpdBrkModlRaw
        enable-take-address=false, indirect-api=false, port=FordVehSpdOverGndRaw
        enable-take-address=false, indirect-api=false, port=FordVehSpdOverGndVld
        enable-take-address=false, indirect-api=false, port=FordVehSteerPinionAgOffsRaw
        enable-take-address=false, indirect-api=false, port=FordVehSteerPinionAgOffsVld
        enable-take-address=false, indirect-api=false, port=FordVehSteerPinionOffsStsRaw
        enable-take-address=false, indirect-api=false, port=FordVehTireCircum
        enable-take-address=false, indirect-api=false, port=FordVehTrlrAgOffsDirRaw
        enable-take-address=false, indirect-api=false, port=FordVehTrlrAidAcqSts
        enable-take-address=false, indirect-api=false, port=FordVehTrlrAidAvlRaw
        enable-take-address=false, indirect-api=false, port=FordVehTrlrAidCnclReq
        enable-take-address=false, indirect-api=false, port=FordVehTrlrAidCnclReqVld
        enable-take-address=false, indirect-api=false, port=FordVehTrlrAidHitchAg
        enable-take-address=false, indirect-api=false, port=FordVehTrlrAidIdnNrRaw
        enable-take-address=false, indirect-api=false, port=FordVehTrlrAidIdnVal
        enable-take-address=false, indirect-api=false, port=FordVehTrlrAidKnobBtn
        enable-take-address=false, indirect-api=false, port=FordVehTrlrAidKnobPosn
        enable-take-address=false, indirect-api=false, port=FordVehTrlrAidKnobPosnVld
        enable-take-address=false, indirect-api=false, port=FordVehTrlrAidKnobStsVld
        enable-take-address=false, indirect-api=false, port=FordVehTrlrAidModReq
        enable-take-address=false, indirect-api=false, port=FordVehTrlrAidModReqVld
        enable-take-address=false, indirect-api=false, port=FordVehTrlrAidSetUpRaw
        enable-take-address=false, indirect-api=false, port=FordVehTrlrAidTrakgSt
        enable-take-address=false, indirect-api=false, port=FordVehTrlrAidTrakgStVld
        enable-take-address=false, indirect-api=false, port=FordVehTrlrAidTrlrRvsGuidcSts
        enable-take-address=false, indirect-api=false, port=FordVehTrlrAxleToBmpRaw
        enable-take-address=false, indirect-api=false, port=FordVehTrlrBackupAssiAvlVld
        enable-take-address=false, indirect-api=false, port=FordVehTrlrBackupAssiMeasVld
        enable-take-address=false, indirect-api=false, port=FordVehTrlrBallToAxle
        enable-take-address=false, indirect-api=false, port=FordVehTrlrBrkCnctnStsRaw
        enable-take-address=false, indirect-api=false, port=FordVehTrlrEnaReqRaw
        enable-take-address=false, indirect-api=false, port=FordVehTrlrHitchAgRateRaw
        enable-take-address=false, indirect-api=false, port=FordVehTrlrHitchAgVld
        enable-take-address=false, indirect-api=false, port=FordVehTrlrHitchRateVld
        enable-take-address=false, indirect-api=false, port=FordVehTrlrHitchYawAgRaw
        enable-take-address=false, indirect-api=false, port=FordVehTrlrHitchYawSts
        enable-take-address=false, indirect-api=false, port=FordVehTrlrIdnTypRaw
        enable-take-address=false, indirect-api=false, port=FordVehTrlrLampCnctnStsRaw
        enable-take-address=false, indirect-api=false, port=FordVehTrlrRvsCnclReqRaw
        enable-take-address=false, indirect-api=false, port=FordVehTrlrRvsEnaRaw
        enable-take-address=false, indirect-api=false, port=FordVehTrlrRvsMsgTxtReqRaw
        enable-take-address=false, indirect-api=false, port=FordVehTrlrTarVld
        enable-take-address=false, indirect-api=false, port=FordVehTrlrYawRateQlyFac
        enable-take-address=false, indirect-api=false, port=FordVehTrlrYawRateRaw
        enable-take-address=false, indirect-api=false, port=FordVehTrsmDesGearRaw
        enable-take-address=false, indirect-api=false, port=FordVehTurnSigSwtStsRaw
        enable-take-address=false, indirect-api=false, port=FordVehTurnSigVld
        enable-take-address=false, indirect-api=false, port=FordVehVertACmpdRaw
        enable-take-address=false, indirect-api=false, port=FordVehYawRateCmpdRaw
        enable-take-address=false, indirect-api=false, port=FordVehYawRateRaw
        enable-take-address=false, indirect-api=false, port=FordVehYawRateRawVld
        enable-take-address=false, indirect-api=false, port=FordVehYawRateVld
        enable-take-address=false, indirect-api=false, port=FordVehYawStabyRaw
        enable-take-address=false, indirect-api=false, port=FordVehYawStabyVld
        enable-take-address=false, indirect-api=false, port=FordYawRateSnsrIdHi
        enable-take-address=false, indirect-api=false, port=FordYawRateSnsrIdLo
        enable-take-address=false, indirect-api=false, port=HwVel
        enable-take-address=false, indirect-api=false, port=IntAgCtrlSt
        enable-take-address=false, indirect-api=false, port=RackToPinionRat
        enable-take-address=false, indirect-api=false, port=SelnDrvgModSteerModReq
        enable-take-address=false, indirect-api=false, port=SemiAutParlParkAgCtrlSts{1..5}
        enable-take-address=false, indirect-api=false, port=TrlrBackupAssiEnaVld
        enable-take-address=false, indirect-api=false, port=TrlrBackupAssiRvsVld
        enable-take-address=false, indirect-api=false, port=TrlrBackupAssiYawRateVld
        enable-take-address=false, indirect-api=false, port=VehSpd
        enable-take-address=false, indirect-api=false, port=VehSpdVld
        enable-take-address=false, indirect-api=false, port=VehSteerRat
        enable-take-address=false, indirect-api=false, port=VehWhlBas
        enable-take-address=false, indirect-api=false, port=VertAVld
      runnable FordBlaBoxIfCmnInit1
        data-receive-point-by-arguments:
          198 x access:
            REC_ActvParkAssiTqFild_Val: accessed-variable=ActvParkAssiTqFild.Val
            REC_EcuId_Val: accessed-variable=EcuId.Val
            REC_EngTqClass_Val: accessed-variable=EngTqClass.Val
            REC_FildVehSpdVld_Logl: accessed-variable=FildVehSpdVld.Logl
            REC_FordActvNiblCtrlEnad_Logl: accessed-variable=FordActvNiblCtrlEnad.Logl
            REC_FordAppldFinalMotTq_Val_1: accessed-variable=FordAppldFinalMotTq.Val
            REC_FordAppldFinalMotTqVld_Logl: accessed-variable=FordAppldFinalMotTqVld.Logl
            REC_FordBoostCrvAssiTq_Val: accessed-variable=FordBoostCrvAssiTq.Val
            REC_FordBoostCrvInpTq_Val: accessed-variable=FordBoostCrvInpTq.Val
            REC_FordBrkPlsRejctnEnad_Logl: accessed-variable=FordBrkPlsRejctnEnad.Logl
            REC_FordCmpdHwPosn_Val: accessed-variable=FordCmpdHwPosn.Val
            REC_FordCmpdHwPosnQlyFac_Val_1: accessed-variable=FordCmpdHwPosnQlyFac.Val
            REC_FordEvasSteerAssiEnad_Logl: accessed-variable=FordEvasSteerAssiEnad.Logl
            REC_FordEvasSteerAssiEnaReq_Val: accessed-variable=FordEvasSteerAssiEnaReq.Val
            REC_FordHwVelVld_Logl: accessed-variable=FordHwVelVld.Logl
            REC_FordInpTqRaw_Val: accessed-variable=FordInpTqRaw.Val
            REC_FordInpTqRawVld_Logl: accessed-variable=FordInpTqRawVld.Logl
            REC_FordLaneCentrAssiEnad_Logl: accessed-variable=FordLaneCentrAssiEnad.Logl
            REC_FordLaneDprtrWarnEnad_Logl: accessed-variable=FordLaneDprtrWarnEnad.Logl
            REC_FordLaneKeepAssiEnad_Logl: accessed-variable=FordLaneKeepAssiEnad.Logl
            REC_FordMaxAsscTq_Val: accessed-variable=FordMaxAsscTq.Val
            REC_FordMsgInp{1..4}Vld_Logl: accessed-variable=FordMsgInp{1..4}Vld.Logl
            REC_FordPullDriftCmpEnad_Logl: accessed-variable=FordPullDriftCmpEnad.Logl
            REC_FordRelHwPosn_Val: accessed-variable=FordRelHwPosn.Val
            REC_FordRelHwPosnVld_Logl: accessed-variable=FordRelHwPosnVld.Logl
            REC_FordReqdFinalMotTq_Val_1: accessed-variable=FordReqdFinalMotTq.Val
            REC_FordResrchFctEnad_Logl: accessed-variable=FordResrchFctEnad.Logl
            REC_FordTqSteerCmpEnad_Logl: accessed-variable=FordTqSteerCmpEnad.Logl
            REC_FordTrfcJamAssiEnad_Logl: accessed-variable=FordTrfcJamAssiEnad.Logl
            REC_FordTrlrAidHitchAgRate_Val: accessed-variable=FordTrlrAidHitchAgRate.Val
            REC_FordTrlrBackupAssi5WhlEnad_Logl: accessed-variable=FordTrlrBackupAssi5WhlEnad.Logl
            REC_FordTrlrBackupAssiEnad_Logl: accessed-variable=FordTrlrBackupAssiEnad.Logl
            REC_FordTrlrBackupAssiTrigEnad_Logl: accessed-variable=FordTrlrBackupAssiTrigEnad.Logl
            REC_FordVehAbsActv_Val: accessed-variable=FordVehAbsActv.Val
            REC_FordVehAbsEscStsVld_Logl: accessed-variable=FordVehAbsEscStsVld.Logl
            REC_FordVehAccrPedlPosnStsQlyFacRaw_Val: accessed-variable=FordVehAccrPedlPosnStsQlyFacRaw.Val
            REC_FordVehAccrPedlPosnStsRaw_Val: accessed-variable=FordVehAccrPedlPosnStsRaw.Val
            REC_FordVehAccrPedlPosnStsVld_Logl: accessed-variable=FordVehAccrPedlPosnStsVld.Logl
            REC_FordVehActBrkTqRaw_Val: accessed-variable=FordVehActBrkTqRaw.Val
            REC_FordVehBlaBoxInp1HiPart_Val: accessed-variable=FordVehBlaBoxInp1HiPart.Val
            REC_FordVehBlaBoxInp1LoPart_Val: accessed-variable=FordVehBlaBoxInp1LoPart.Val
            REC_FordVehBlaBoxInp2HiPart_Val: accessed-variable=FordVehBlaBoxInp2HiPart.Val
            REC_FordVehBlaBoxInp2LoPart_Val: accessed-variable=FordVehBlaBoxInp2LoPart.Val
            REC_FordVehBlaBoxInp3HiPart_Val: accessed-variable=FordVehBlaBoxInp3HiPart.Val
            REC_FordVehBlaBoxInp3LoPart_Val: accessed-variable=FordVehBlaBoxInp3LoPart.Val
            REC_FordVehBlaBoxInp4HiPart_Val: accessed-variable=FordVehBlaBoxInp4HiPart.Val
            REC_FordVehBlaBoxInp4LoPart_Val: accessed-variable=FordVehBlaBoxInp4LoPart.Val
            REC_FordVehBrkPedlAppld_Val: accessed-variable=FordVehBrkPedlAppld.Val
            REC_FordVehBrkPedlAppldQlyFac_Val: accessed-variable=FordVehBrkPedlAppldQlyFac.Val
            REC_FordVehBrkPedlVld_Logl: accessed-variable=FordVehBrkPedlVld.Logl
            REC_FordVehBrkTqVld_Logl: accessed-variable=FordVehBrkTqVld.Logl
            REC_FordVehCllsnMtgtnByBrkgDenied_Val: accessed-variable=FordVehCllsnMtgtnByBrkgDenied.Val
            REC_FordVehCllsnMtgtnByBrkgDisad_Val: accessed-variable=FordVehCllsnMtgtnByBrkgDisad.Val
            REC_FordVehCllsnMtgtnByBrkgLatDstRaw_Val: accessed-variable=FordVehCllsnMtgtnByBrkgLatDstRaw.Val
            REC_FordVehCllsnMtgtnByBrkgLgtDstRaw_Val: accessed-variable=FordVehCllsnMtgtnByBrkgLgtDstRaw.Val
            REC_FordVehCllsnMtgtnByBrkgObjDataConfLvlRaw_Val: accessed-variable=FordVehCllsnMtgtnByBrkgObjDataConfLvlRaw.Val
            REC_FordVehCllsnMtgtnByBrkgObjTypClassnRaw_Val: accessed-variable=FordVehCllsnMtgtnByBrkgObjTypClassnRaw.Val
            REC_FordVehCllsnMtgtnByBrkgRelLatVelRaw_Val: accessed-variable=FordVehCllsnMtgtnByBrkgRelLatVelRaw.Val
            REC_FordVehCllsnMtgtnByBrkgRelLgtVelRaw_Val: accessed-variable=FordVehCllsnMtgtnByBrkgRelLgtVelRaw.Val
            REC_FordVehCllsnMtgtnByBrkgTiToCllsnRaw_Val: accessed-variable=FordVehCllsnMtgtnByBrkgTiToCllsnRaw.Val
            REC_FordVehEngSpdRaw_Val: accessed-variable=FordVehEngSpdRaw.Val
            REC_FordVehEngSpdVld_Logl: accessed-variable=FordVehEngSpdVld.Logl
            REC_FordVehEscActv_Val: accessed-variable=FordVehEscActv.Val
            REC_FordVehEvasSteerAssiImgProcrModlAVld_Logl: accessed-variable=FordVehEvasSteerAssiImgProcrModlAVld.Logl
            REC_FordVehEvasSteerAssiReq_Val: accessed-variable=FordVehEvasSteerAssiReq.Val
            REC_FordVehEvasSteerAssiReqVld_Logl: accessed-variable=FordVehEvasSteerAssiReqVld.Logl
            REC_FordVehFrntLeWhlCntrDirVld_Logl: accessed-variable=FordVehFrntLeWhlCntrDirVld.Logl
            REC_FordVehFrntLeWhlDirRaw_Val: accessed-variable=FordVehFrntLeWhlDirRaw.Val
            REC_FordVehFrntLeWhlRollgCntr_Val: accessed-variable=FordVehFrntLeWhlRollgCntr.Val
            REC_FordVehFrntLeWhlSpdRaw_Val: accessed-variable=FordVehFrntLeWhlSpdRaw.Val
            REC_FordVehFrntLeWhlSpdVld_Logl: accessed-variable=FordVehFrntLeWhlSpdVld.Logl
            REC_FordVehFrntRiWhlCntrDirVld_Logl: accessed-variable=FordVehFrntRiWhlCntrDirVld.Logl
            REC_FordVehFrntRiWhlDirRaw_Val: accessed-variable=FordVehFrntRiWhlDirRaw.Val
            REC_FordVehFrntRiWhlRollgCntr_Val: accessed-variable=FordVehFrntRiWhlRollgCntr.Val
            REC_FordVehFrntRiWhlSpdRaw_Val: accessed-variable=FordVehFrntRiWhlSpdRaw.Val
            REC_FordVehFrntRiWhlSpdVld_Logl: accessed-variable=FordVehFrntRiWhlSpdVld.Logl
            REC_FordVehGearLvrPosn_Val: accessed-variable=FordVehGearLvrPosn.Val
            REC_FordVehGearLvrPosnVldInt_Logl: accessed-variable=FordVehGearLvrPosnVldInt.Logl
            REC_FordVehGearPosnRaw_Val: accessed-variable=FordVehGearPosnRaw.Val
            REC_FordVehGearRvsStsRaw_Val: accessed-variable=FordVehGearRvsStsRaw.Val
            REC_FordVehGearRvsStsVld_Logl: accessed-variable=FordVehGearRvsStsVld.Logl
            REC_FordVehIgnSts_Val: accessed-variable=FordVehIgnSts.Val
            REC_FordVehIgnStsVld_Logl: accessed-variable=FordVehIgnStsVld.Logl
            REC_FordVehLaneAssiImgProcgModlAVld_Logl: accessed-variable=FordVehLaneAssiImgProcgModlAVld.Logl
            REC_FordVehLaneDetnWarnInten_Val: accessed-variable=FordVehLaneDetnWarnInten.Val
            REC_FordVehLaneDetnWarnSts_Val: accessed-variable=FordVehLaneDetnWarnSts.Val
            REC_FordVehLaneKeepSysCrvtRaw_Val: accessed-variable=FordVehLaneKeepSysCrvtRaw.Val
            REC_FordVehLaneKeepSysRampTyp_Val: accessed-variable=FordVehLaneKeepSysRampTyp.Val
            REC_FordVehLaneKeepSysReqdAg_Val: accessed-variable=FordVehLaneKeepSysReqdAgRaw.Val
            REC_FordVehLaneKeepSysSts_Val: accessed-variable=FordVehLaneKeepSysSts.Val
            REC_FordVehLatACmpdRaw_Val: accessed-variable=FordVehLatACmpdRaw.Val
            REC_FordVehLatACmpdVld_Logl: accessed-variable=FordVehLatACmpdVld.Logl
            REC_FordVehLatCtrlCrvtRateRaw_Val: accessed-variable=FordVehLatCtrlCrvtRateRaw.Val
            REC_FordVehLatCtrlCrvtRaw_Val: accessed-variable=FordVehLatCtrlCrvtRaw.Val
            REC_FordVehLatCtrlHandsOffDetnTqStimlsReq_Val: accessed-variable=FordVehLatCtrlHandsOffDetnTqStimlsReq.Val
            REC_FordVehLatCtrlImgProcrModlAVld_Logl: accessed-variable=FordVehLatCtrlImgProcrModlAVld.Logl
            REC_FordVehLatCtrlPahOffsRaw_Val: accessed-variable=FordVehLatCtrlPahOffsRaw.Val
            REC_FordVehLatCtrlPahRaw_Val: accessed-variable=FordVehLatCtrlPahRaw.Val
            REC_FordVehLatCtrlPrcsn_Val: accessed-variable=FordVehLatCtrlPrcsn.Val
            REC_FordVehLatCtrlRampTyp_Val: accessed-variable=FordVehLatCtrlRampTyp.Val
            REC_FordVehLatCtrlReq_Val: accessed-variable=FordVehLatCtrlReq.Val
            REC_FordVehLatCtrlRingMax_Val: accessed-variable=FordVehLatCtrlRingMax.Val
            REC_FordVehLgtACmpdRaw_Val: accessed-variable=FordVehLgtACmpdRaw.Val
            REC_FordVehLgtACmpdVld_Logl: accessed-variable=FordVehLgtACmpdVld.Logl
            REC_FordVehLoSpdMtnCtrlBrkSprtStsRaw_Val: accessed-variable=FordVehLoSpdMtnCtrlBrkSprtStsRaw.Val
            REC_FordVehLoSpdMtnCtrlBrkSprtVld_Logl: accessed-variable=FordVehLoSpdMtnCtrlBrkSprtVld.Logl
            REC_FordVehParkAidModlStsVld_Logl: accessed-variable=FordVehParkAidModlStsVld.Logl
            REC_FordVehParkAidModlSysSt_Val: accessed-variable=FordVehParkAidModlSysSt.Val
            REC_FordVehPrpnWhlTqRaw_Val: accessed-variable=FordVehPrpnWhlTqRaw.Val
            REC_FordVehPrpnWhlTqVld_Logl: accessed-variable=FordVehPrpnWhlTqVld.Logl
            REC_FordVehReLeWhlCntrDirVld_Logl: accessed-variable=FordVehReLeWhlCntrDirVld.Logl
            REC_FordVehReLeWhlDirRaw_Val: accessed-variable=FordVehReLeWhlDirRaw.Val
            REC_FordVehReLeWhlRollgCntr_Val: accessed-variable=FordVehReLeWhlRollgCntr.Val
            REC_FordVehReLeWhlSpdRaw_Val: accessed-variable=FordVehReLeWhlSpdRaw.Val
            REC_FordVehReLeWhlSpdVld_Logl: accessed-variable=FordVehReLeWhlSpdVld.Logl
            REC_FordVehReRiWhlCntrDirVld_Logl: accessed-variable=FordVehReRiWhlCntrDirVld.Logl
            REC_FordVehReRiWhlDirRaw_Val: accessed-variable=FordVehReRiWhlDirRaw.Val
            REC_FordVehReRiWhlRollgCntr_Val: accessed-variable=FordVehReRiWhlRollgCntr.Val
            REC_FordVehReRiWhlSpdRaw_Val: accessed-variable=FordVehReRiWhlSpdRaw.Val
            REC_FordVehReRiWhlSpdVld_Logl: accessed-variable=FordVehReRiWhlSpdVld.Logl
            REC_FordVehSelDrvModChassisVld_Logl: accessed-variable=FordVehSelDrvModChassisVld.Logl
            REC_FordVehSpd_Val: accessed-variable=FordVehSpd.Val
            REC_FordVehSpdBrkModlRaw_Val: accessed-variable=FordVehSpdBrkModlRaw.Val
            REC_FordVehSpdOverGndRaw_Val: accessed-variable=FordVehSpdOverGndRaw.Val
            REC_FordVehSpdOverGndVld_Logl: accessed-variable=FordVehSpdOverGndVld.Logl
            REC_FordVehSteerPinionAgOffsRaw_Val: accessed-variable=FordVehSteerPinionAgOffsRaw.Val
            REC_FordVehSteerPinionAgOffsVld_Logl: accessed-variable=FordVehSteerPinionAgOffsVld.Logl
            REC_FordVehSteerPinionOffsStsRaw_Val: accessed-variable=FordVehSteerPinionOffsStsRaw.Val
            REC_FordVehTireCircum_Val: accessed-variable=FordVehTireCircum.Val
            REC_FordVehTrlrAgOffsDirRaw_Val: accessed-variable=FordVehTrlrAgOffsDirRaw.Val
            REC_FordVehTrlrAidAcqSts_Val: accessed-variable=FordVehTrlrAidAcqSts.Val
            REC_FordVehTrlrAidAvlRaw_Val: accessed-variable=FordVehTrlrAidAvlRaw.Val
            REC_FordVehTrlrAidCnclReq_Val: accessed-variable=FordVehTrlrAidCnclReq.Val
            REC_FordVehTrlrAidCnclReqVld_Logl: accessed-variable=FordVehTrlrAidCnclReqVld.Logl
            REC_FordVehTrlrAidHitchAg_Val: accessed-variable=FordVehTrlrAidHitchAg.Val
            REC_FordVehTrlrAidIdnNrRaw_Val: accessed-variable=FordVehTrlrAidIdnNrRaw.Val
            REC_FordVehTrlrAidIdnVal_Val: accessed-variable=FordVehTrlrAidIdnVal.Val
            REC_FordVehTrlrAidKnobBtn_Val: accessed-variable=FordVehTrlrAidKnobBtn.Val
            REC_FordVehTrlrAidKnobPosn_Val: accessed-variable=FordVehTrlrAidKnobPosn.Val
            REC_FordVehTrlrAidKnobPosnVld_Logl: accessed-variable=FordVehTrlrAidKnobPosnVld.Logl
            REC_FordVehTrlrAidKnobStsVld_Logl: accessed-variable=FordVehTrlrAidKnobStsVld.Logl
            REC_FordVehTrlrAidModReq_Val: accessed-variable=FordVehTrlrAidModReq.Val
            REC_FordVehTrlrAidModReqVld_Logl: accessed-variable=FordVehTrlrAidModReqVld.Logl
            REC_FordVehTrlrAidSetUpRaw_Val: accessed-variable=FordVehTrlrAidSetUpRaw.Val
            REC_FordVehTrlrAidTrakgSt_Val: accessed-variable=FordVehTrlrAidTrakgSt.Val
            REC_FordVehTrlrAidTrakgStVld_Logl: accessed-variable=FordVehTrlrAidTrakgStVld.Logl
            REC_FordVehTrlrAidTrlrRvsGuidcSts_Val: accessed-variable=FordVehTrlrAidTrlrRvsGuidcSts.Val
            REC_FordVehTrlrAxleToBmpRaw_Val: accessed-variable=FordVehTrlrAxleToBmpRaw.Val
            REC_FordVehTrlrBackupAssiAvlVld_Logl: accessed-variable=FordVehTrlrBackupAssiAvlVld.Logl
            REC_FordVehTrlrBackupAssiMeasVld_Logl: accessed-variable=FordVehTrlrBackupAssiMeasVld.Logl
            REC_FordVehTrlrBallToAxle_Val: accessed-variable=FordVehTrlrBallToAxle.Val
            REC_FordVehTrlrBrkCnctnStsRaw_Val: accessed-variable=FordVehTrlrBrkCnctnStsRaw.Val
            REC_FordVehTrlrEnaReqRaw_Val: accessed-variable=FordVehTrlrEnaReqRaw.Val
            REC_FordVehTrlrHitchAgRateRaw_Val: accessed-variable=FordVehTrlrHitchAgRateRaw.Val
            REC_FordVehTrlrHitchAgVld_Logl: accessed-variable=FordVehTrlrHitchAgVld.Logl
            REC_FordVehTrlrHitchRateVld_Logl: accessed-variable=FordVehTrlrHitchRateVld.Logl
            REC_FordVehTrlrHitchYawAgRaw_Val: accessed-variable=FordVehTrlrHitchYawAgRaw.Val
            REC_FordVehTrlrHitchYawSts_Val: accessed-variable=FordVehTrlrHitchYawSts.Val
            REC_FordVehTrlrIdnTypRaw_Val: accessed-variable=FordVehTrlrIdnTypRaw.Val
            REC_FordVehTrlrLampCnctnStsRaw_Val: accessed-variable=FordVehTrlrLampCnctnStsRaw.Val
            REC_FordVehTrlrRvsCnclReqRaw_Val: accessed-variable=FordVehTrlrRvsCnclReqRaw.Val
            REC_FordVehTrlrRvsEnaRaw_Val: accessed-variable=FordVehTrlrRvsEnaRaw.Val
            REC_FordVehTrlrRvsMsgTxtReqRaw_Val: accessed-variable=FordVehTrlrRvsMsgTxtReqRaw.Val
            REC_FordVehTrlrTarVld_Logl: accessed-variable=FordVehTrlrTarVld.Logl
            REC_FordVehTrlrYawRateQlyFac_Val: accessed-variable=FordVehTrlrYawRateQlyFac.Val
            REC_FordVehTrlrYawRateRaw_Val: accessed-variable=FordVehTrlrYawRateRaw.Val
            REC_FordVehTrsmDesGearRaw_Val: accessed-variable=FordVehTrsmDesGearRaw.Val
            REC_FordVehTurnSigSwtStsRaw_Val: accessed-variable=FordVehTurnSigSwtStsRaw.Val
            REC_FordVehTurnSigVld_Logl: accessed-variable=FordVehTurnSigVld.Logl
            REC_FordVehVertACmpdRaw_Val: accessed-variable=FordVehVertACmpdRaw.Val
            REC_FordVehYawRateCmpdRaw_Val: accessed-variable=FordVehYawRateCmpdRaw.Val
            REC_FordVehYawRateRaw_Ford_VehYaw_W_Actl: accessed-variable=FordVehYawRateRaw.Ford_VehYaw_W_Actl
            REC_FordVehYawRateRawVld_Logl: accessed-variable=FordVehYawRateRawVld.Logl
            REC_FordVehYawRateVld_Logl: accessed-variable=FordVehYawRateVld.Logl
            REC_FordVehYawStabyRaw_Val: accessed-variable=FordVehYawStabyRaw.Val
            REC_FordVehYawStabyVld_Logl: accessed-variable=FordVehYawStabyVld.Logl
            REC_FordYawRateSnsrIdHi_Val: accessed-variable=FordYawRateSnsrIdHi.Val
            REC_FordYawRateSnsrIdLo_Val: accessed-variable=FordYawRateSnsrIdLo.Val
            REC_HwVel_Val: accessed-variable=HwVel.Val
            REC_IntAgCtrlSt_Val: accessed-variable=IntAgCtrlSt.Val
            REC_RackToPinionRat_Val: accessed-variable=RackToPinionRat.Val
            REC_SelnDrvgModSteerModReq_Val: accessed-variable=SelnDrvgModSteerModReq.Val
            REC_SemiAutParlParkAgCtrlSts1_Val: accessed-variable=SemiAutParlParkAgCtrlSts1.Val
            REC_SemiAutParlParkAgCtrlSts{2..5}_Logl: accessed-variable=SemiAutParlParkAgCtrlSts{2..5}.Logl
            REC_TrlrBackupAssiEnaVld_Logl: accessed-variable=TrlrBackupAssiEnaVld.Logl
            REC_TrlrBackupAssiRvsVld_Logl: accessed-variable=TrlrBackupAssiRvsVld.Logl
            REC_TrlrBackupAssiYawRateVld_Logl: accessed-variable=TrlrBackupAssiYawRateVld.Logl
            REC_VehSpd_Val: accessed-variable=VehSpd.Val
            REC_VehSpdVld_Logl: accessed-variable=VehSpdVld.Logl
            REC_VehSteerRat_Val: accessed-variable=VehSteerRat.Val
            REC_VehWhlBas_Val: accessed-variable=VehWhlBas.Val
            REC_VertAVld_Logl: accessed-variable=VertAVld.Logl
      runnable FordBlaBoxIfCmnPer1
        data-receive-point-by-arguments:
          198 x access:
            REC_ActvParkAssiTqFild_Val: accessed-variable=ActvParkAssiTqFild.Val
            REC_EcuId_Val: accessed-variable=EcuId.Val
            REC_EngTqClass_Val: accessed-variable=EngTqClass.Val
            REC_FildVehSpdVld_Logl: accessed-variable=FildVehSpdVld.Logl
            REC_FordActvNiblCtrlEnad_Logl: accessed-variable=FordActvNiblCtrlEnad.Logl
            REC_FordAppldFinalMotTq_Val_1: accessed-variable=FordAppldFinalMotTq.Val
            REC_FordAppldFinalMotTqVld_Logl: accessed-variable=FordAppldFinalMotTqVld.Logl
            REC_FordBoostCrvAssiTq_Val: accessed-variable=FordBoostCrvAssiTq.Val
            REC_FordBoostCrvInpTq_Val: accessed-variable=FordBoostCrvInpTq.Val
            REC_FordBrkPlsRejctnEnad_Logl: accessed-variable=FordBrkPlsRejctnEnad.Logl
            REC_FordCmpdHwPosn_Val: accessed-variable=FordCmpdHwPosn.Val
            REC_FordCmpdHwPosnQlyFac_Val_1: accessed-variable=FordCmpdHwPosnQlyFac.Val
            REC_FordEvasSteerAssiEnad_Logl: accessed-variable=FordEvasSteerAssiEnad.Logl
            REC_FordEvasSteerAssiEnaReq_Val: accessed-variable=FordEvasSteerAssiEnaReq.Val
            REC_FordHwVelVld_Logl: accessed-variable=FordHwVelVld.Logl
            REC_FordInpTqRaw_Val: accessed-variable=FordInpTqRaw.Val
            REC_FordInpTqRawVld_Logl: accessed-variable=FordInpTqRawVld.Logl
            REC_FordLaneCentrAssiEnad_Logl: accessed-variable=FordLaneCentrAssiEnad.Logl
            REC_FordLaneDprtrWarnEnad_Logl: accessed-variable=FordLaneDprtrWarnEnad.Logl
            REC_FordLaneKeepAssiEnad_Logl: accessed-variable=FordLaneKeepAssiEnad.Logl
            REC_FordMaxAsscTq_Val: accessed-variable=FordMaxAsscTq.Val
            REC_FordMsgInp{1..4}Vld_Logl: accessed-variable=FordMsgInp{1..4}Vld.Logl
            REC_FordPullDriftCmpEnad_Logl: accessed-variable=FordPullDriftCmpEnad.Logl
            REC_FordRelHwPosn_Val: accessed-variable=FordRelHwPosn.Val
            REC_FordRelHwPosnVld_Logl: accessed-variable=FordRelHwPosnVld.Logl
            REC_FordReqdFinalMotTq_Val_1: accessed-variable=FordReqdFinalMotTq.Val
            REC_FordResrchFctEnad_Logl: accessed-variable=FordResrchFctEnad.Logl
            REC_FordTqSteerCmpEnad_Logl: accessed-variable=FordTqSteerCmpEnad.Logl
            REC_FordTrfcJamAssiEnad_Logl: accessed-variable=FordTrfcJamAssiEnad.Logl
            REC_FordTrlrAidHitchAgRate_Val: accessed-variable=FordTrlrAidHitchAgRate.Val
            REC_FordTrlrBackupAssi5WhlEnad_Logl: accessed-variable=FordTrlrBackupAssi5WhlEnad.Logl
            REC_FordTrlrBackupAssiEnad_Logl: accessed-variable=FordTrlrBackupAssiEnad.Logl
            REC_FordTrlrBackupAssiTrigEnad_Logl: accessed-variable=FordTrlrBackupAssiTrigEnad.Logl
            REC_FordVehAbsActv_Val: accessed-variable=FordVehAbsActv.Val
            REC_FordVehAbsEscStsVld_Logl: accessed-variable=FordVehAbsEscStsVld.Logl
            REC_FordVehAccrPedlPosnStsQlyFacRaw_Val: accessed-variable=FordVehAccrPedlPosnStsQlyFacRaw.Val
            REC_FordVehAccrPedlPosnStsRaw_Val: accessed-variable=FordVehAccrPedlPosnStsRaw.Val
            REC_FordVehAccrPedlPosnStsVld_Logl: accessed-variable=FordVehAccrPedlPosnStsVld.Logl
            REC_FordVehActBrkTqRaw_Val: accessed-variable=FordVehActBrkTqRaw.Val
            REC_FordVehBlaBoxInp1HiPart_Val: accessed-variable=FordVehBlaBoxInp1HiPart.Val
            REC_FordVehBlaBoxInp1LoPart_Val: accessed-variable=FordVehBlaBoxInp1LoPart.Val
            REC_FordVehBlaBoxInp2HiPart_Val: accessed-variable=FordVehBlaBoxInp2HiPart.Val
            REC_FordVehBlaBoxInp2LoPart_Val: accessed-variable=FordVehBlaBoxInp2LoPart.Val
            REC_FordVehBlaBoxInp3HiPart_Val: accessed-variable=FordVehBlaBoxInp3HiPart.Val
            REC_FordVehBlaBoxInp3LoPart_Val: accessed-variable=FordVehBlaBoxInp3LoPart.Val
            REC_FordVehBlaBoxInp4HiPart_Val: accessed-variable=FordVehBlaBoxInp4HiPart.Val
            REC_FordVehBlaBoxInp4LoPart_Val: accessed-variable=FordVehBlaBoxInp4LoPart.Val
            REC_FordVehBrkPedlAppld_Val: accessed-variable=FordVehBrkPedlAppld.Val
            REC_FordVehBrkPedlAppldQlyFac_Val: accessed-variable=FordVehBrkPedlAppldQlyFac.Val
            REC_FordVehBrkPedlVld_Logl: accessed-variable=FordVehBrkPedlVld.Logl
            REC_FordVehBrkTqVld_Logl: accessed-variable=FordVehBrkTqVld.Logl
            REC_FordVehCllsnMtgtnByBrkgDenied_Val: accessed-variable=FordVehCllsnMtgtnByBrkgDenied.Val
            REC_FordVehCllsnMtgtnByBrkgDisad_Val: accessed-variable=FordVehCllsnMtgtnByBrkgDisad.Val
            REC_FordVehCllsnMtgtnByBrkgLatDstRaw_Val: accessed-variable=FordVehCllsnMtgtnByBrkgLatDstRaw.Val
            REC_FordVehCllsnMtgtnByBrkgLgtDstRaw_Val: accessed-variable=FordVehCllsnMtgtnByBrkgLgtDstRaw.Val
            REC_FordVehCllsnMtgtnByBrkgObjDataConfLvlRaw_Val: accessed-variable=FordVehCllsnMtgtnByBrkgObjDataConfLvlRaw.Val
            REC_FordVehCllsnMtgtnByBrkgObjTypClassnRaw_Val: accessed-variable=FordVehCllsnMtgtnByBrkgObjTypClassnRaw.Val
            REC_FordVehCllsnMtgtnByBrkgRelLatVelRaw_Val: accessed-variable=FordVehCllsnMtgtnByBrkgRelLatVelRaw.Val
            REC_FordVehCllsnMtgtnByBrkgRelLgtVelRaw_Val: accessed-variable=FordVehCllsnMtgtnByBrkgRelLgtVelRaw.Val
            REC_FordVehCllsnMtgtnByBrkgTiToCllsnRaw_Val: accessed-variable=FordVehCllsnMtgtnByBrkgTiToCllsnRaw.Val
            REC_FordVehEngSpdRaw_Val: accessed-variable=FordVehEngSpdRaw.Val
            REC_FordVehEngSpdVld_Logl: accessed-variable=FordVehEngSpdVld.Logl
            REC_FordVehEscActv_Val: accessed-variable=FordVehEscActv.Val
            REC_FordVehEvasSteerAssiImgProcrModlAVld_Logl: accessed-variable=FordVehEvasSteerAssiImgProcrModlAVld.Logl
            REC_FordVehEvasSteerAssiReq_Val: accessed-variable=FordVehEvasSteerAssiReq.Val
            REC_FordVehEvasSteerAssiReqVld_Logl: accessed-variable=FordVehEvasSteerAssiReqVld.Logl
            REC_FordVehFrntLeWhlCntrDirVld_Logl: accessed-variable=FordVehFrntLeWhlCntrDirVld.Logl
            REC_FordVehFrntLeWhlDirRaw_Val: accessed-variable=FordVehFrntLeWhlDirRaw.Val
            REC_FordVehFrntLeWhlRollgCntr_Val: accessed-variable=FordVehFrntLeWhlRollgCntr.Val
            REC_FordVehFrntLeWhlSpdRaw_Val: accessed-variable=FordVehFrntLeWhlSpdRaw.Val
            REC_FordVehFrntLeWhlSpdVld_Logl: accessed-variable=FordVehFrntLeWhlSpdVld.Logl
            REC_FordVehFrntRiWhlCntrDirVld_Logl: accessed-variable=FordVehFrntRiWhlCntrDirVld.Logl
            REC_FordVehFrntRiWhlDirRaw_Val: accessed-variable=FordVehFrntRiWhlDirRaw.Val
            REC_FordVehFrntRiWhlRollgCntr_Val: accessed-variable=FordVehFrntRiWhlRollgCntr.Val
            REC_FordVehFrntRiWhlSpdRaw_Val: accessed-variable=FordVehFrntRiWhlSpdRaw.Val
            REC_FordVehFrntRiWhlSpdVld_Logl: accessed-variable=FordVehFrntRiWhlSpdVld.Logl
            REC_FordVehGearLvrPosn_Val: accessed-variable=FordVehGearLvrPosn.Val
            REC_FordVehGearLvrPosnVldInt_Logl: accessed-variable=FordVehGearLvrPosnVldInt.Logl
            REC_FordVehGearPosnRaw_Val: accessed-variable=FordVehGearPosnRaw.Val
            REC_FordVehGearRvsStsRaw_Val: accessed-variable=FordVehGearRvsStsRaw.Val
            REC_FordVehGearRvsStsVld_Logl: accessed-variable=FordVehGearRvsStsVld.Logl
            REC_FordVehIgnSts_Val: accessed-variable=FordVehIgnSts.Val
            REC_FordVehIgnStsVld_Logl: accessed-variable=FordVehIgnStsVld.Logl
            REC_FordVehLaneAssiImgProcgModlAVld_Logl: accessed-variable=FordVehLaneAssiImgProcgModlAVld.Logl
            REC_FordVehLaneDetnWarnInten_Val: accessed-variable=FordVehLaneDetnWarnInten.Val
            REC_FordVehLaneDetnWarnSts_Val: accessed-variable=FordVehLaneDetnWarnSts.Val
            REC_FordVehLaneKeepSysCrvtRaw_Val: accessed-variable=FordVehLaneKeepSysCrvtRaw.Val
            REC_FordVehLaneKeepSysRampTyp_Val: accessed-variable=FordVehLaneKeepSysRampTyp.Val
            REC_FordVehLaneKeepSysReqdAg_Val: accessed-variable=FordVehLaneKeepSysReqdAgRaw.Val
            REC_FordVehLaneKeepSysSts_Val: accessed-variable=FordVehLaneKeepSysSts.Val
            REC_FordVehLatACmpdRaw_Val: accessed-variable=FordVehLatACmpdRaw.Val
            REC_FordVehLatACmpdVld_Logl: accessed-variable=FordVehLatACmpdVld.Logl
            REC_FordVehLatCtrlCrvtRateRaw_Val: accessed-variable=FordVehLatCtrlCrvtRateRaw.Val
            REC_FordVehLatCtrlCrvtRaw_Val: accessed-variable=FordVehLatCtrlCrvtRaw.Val
            REC_FordVehLatCtrlHandsOffDetnTqStimlsReq_Val: accessed-variable=FordVehLatCtrlHandsOffDetnTqStimlsReq.Val
            REC_FordVehLatCtrlImgProcrModlAVld_Logl: accessed-variable=FordVehLatCtrlImgProcrModlAVld.Logl
            REC_FordVehLatCtrlPahOffsRaw_Val: accessed-variable=FordVehLatCtrlPahOffsRaw.Val
            REC_FordVehLatCtrlPahRaw_Val: accessed-variable=FordVehLatCtrlPahRaw.Val
            REC_FordVehLatCtrlPrcsn_Val: accessed-variable=FordVehLatCtrlPrcsn.Val
            REC_FordVehLatCtrlRampTyp_Val: accessed-variable=FordVehLatCtrlRampTyp.Val
            REC_FordVehLatCtrlReq_Val: accessed-variable=FordVehLatCtrlReq.Val
            REC_FordVehLatCtrlRingMax_Val: accessed-variable=FordVehLatCtrlRingMax.Val
            REC_FordVehLgtACmpdRaw_Val: accessed-variable=FordVehLgtACmpdRaw.Val
            REC_FordVehLgtACmpdVld_Logl: accessed-variable=FordVehLgtACmpdVld.Logl
            REC_FordVehLoSpdMtnCtrlBrkSprtStsRaw_Val: accessed-variable=FordVehLoSpdMtnCtrlBrkSprtStsRaw.Val
            REC_FordVehLoSpdMtnCtrlBrkSprtVld_Logl: accessed-variable=FordVehLoSpdMtnCtrlBrkSprtVld.Logl
            REC_FordVehParkAidModlStsVld_Logl: accessed-variable=FordVehParkAidModlStsVld.Logl
            REC_FordVehParkAidModlSysSt_Val: accessed-variable=FordVehParkAidModlSysSt.Val
            REC_FordVehPrpnWhlTqRaw_Val: accessed-variable=FordVehPrpnWhlTqRaw.Val
            REC_FordVehPrpnWhlTqVld_Logl: accessed-variable=FordVehPrpnWhlTqVld.Logl
            REC_FordVehReLeWhlCntrDirVld_Logl: accessed-variable=FordVehReLeWhlCntrDirVld.Logl
            REC_FordVehReLeWhlDirRaw_Val: accessed-variable=FordVehReLeWhlDirRaw.Val
            REC_FordVehReLeWhlRollgCntr_Val: accessed-variable=FordVehReLeWhlRollgCntr.Val
            REC_FordVehReLeWhlSpdRaw_Val: accessed-variable=FordVehReLeWhlSpdRaw.Val
            REC_FordVehReLeWhlSpdVld_Logl: accessed-variable=FordVehReLeWhlSpdVld.Logl
            REC_FordVehReRiWhlCntrDirVld_Logl: accessed-variable=FordVehReRiWhlCntrDirVld.Logl
            REC_FordVehReRiWhlDirRaw_Val: accessed-variable=FordVehReRiWhlDirRaw.Val
            REC_FordVehReRiWhlRollgCntr_Val: accessed-variable=FordVehReRiWhlRollgCntr.Val
            REC_FordVehReRiWhlSpdRaw_Val: accessed-variable=FordVehReRiWhlSpdRaw.Val
            REC_FordVehReRiWhlSpdVld_Logl: accessed-variable=FordVehReRiWhlSpdVld.Logl
            REC_FordVehSelDrvModChassisVld_Logl: accessed-variable=FordVehSelDrvModChassisVld.Logl
            REC_FordVehSpd_Val: accessed-variable=FordVehSpd.Val
            REC_FordVehSpdBrkModlRaw_Val: accessed-variable=FordVehSpdBrkModlRaw.Val
            REC_FordVehSpdOverGndRaw_Val: accessed-variable=FordVehSpdOverGndRaw.Val
            REC_FordVehSpdOverGndVld_Logl: accessed-variable=FordVehSpdOverGndVld.Logl
            REC_FordVehSteerPinionAgOffsRaw_Val: accessed-variable=FordVehSteerPinionAgOffsRaw.Val
            REC_FordVehSteerPinionAgOffsVld_Logl: accessed-variable=FordVehSteerPinionAgOffsVld.Logl
            REC_FordVehSteerPinionOffsStsRaw_Val: accessed-variable=FordVehSteerPinionOffsStsRaw.Val
            REC_FordVehTireCircum_Val: accessed-variable=FordVehTireCircum.Val
            REC_FordVehTrlrAgOffsDirRaw_Val: accessed-variable=FordVehTrlrAgOffsDirRaw.Val
            REC_FordVehTrlrAidAcqSts_Val: accessed-variable=FordVehTrlrAidAcqSts.Val
            REC_FordVehTrlrAidAvlRaw_Val: accessed-variable=FordVehTrlrAidAvlRaw.Val
            REC_FordVehTrlrAidCnclReq_Val: accessed-variable=FordVehTrlrAidCnclReq.Val
            REC_FordVehTrlrAidCnclReqVld_Logl: accessed-variable=FordVehTrlrAidCnclReqVld.Logl
            REC_FordVehTrlrAidHitchAg_Val: accessed-variable=FordVehTrlrAidHitchAg.Val
            REC_FordVehTrlrAidIdnNrRaw_Val: accessed-variable=FordVehTrlrAidIdnNrRaw.Val
            REC_FordVehTrlrAidIdnVal_Val: accessed-variable=FordVehTrlrAidIdnVal.Val
            REC_FordVehTrlrAidKnobBtn_Val: accessed-variable=FordVehTrlrAidKnobBtn.Val
            REC_FordVehTrlrAidKnobPosn_Val: accessed-variable=FordVehTrlrAidKnobPosn.Val
            REC_FordVehTrlrAidKnobPosnVld_Logl: accessed-variable=FordVehTrlrAidKnobPosnVld.Logl
            REC_FordVehTrlrAidKnobStsVld_Logl: accessed-variable=FordVehTrlrAidKnobStsVld.Logl
            REC_FordVehTrlrAidModReq_Val: accessed-variable=FordVehTrlrAidModReq.Val
            REC_FordVehTrlrAidModReqVld_Logl: accessed-variable=FordVehTrlrAidModReqVld.Logl
            REC_FordVehTrlrAidSetUpRaw_Val: accessed-variable=FordVehTrlrAidSetUpRaw.Val
            REC_FordVehTrlrAidTrakgSt_Val: accessed-variable=FordVehTrlrAidTrakgSt.Val
            REC_FordVehTrlrAidTrakgStVld_Logl: accessed-variable=FordVehTrlrAidTrakgStVld.Logl
            REC_FordVehTrlrAidTrlrRvsGuidcSts_Val: accessed-variable=FordVehTrlrAidTrlrRvsGuidcSts.Val
            REC_FordVehTrlrAxleToBmpRaw_Val: accessed-variable=FordVehTrlrAxleToBmpRaw.Val
            REC_FordVehTrlrBackupAssiAvlVld_Logl: accessed-variable=FordVehTrlrBackupAssiAvlVld.Logl
            REC_FordVehTrlrBackupAssiMeasVld_Logl: accessed-variable=FordVehTrlrBackupAssiMeasVld.Logl
            REC_FordVehTrlrBallToAxle_Val: accessed-variable=FordVehTrlrBallToAxle.Val
            REC_FordVehTrlrBrkCnctnStsRaw_Val: accessed-variable=FordVehTrlrBrkCnctnStsRaw.Val
            REC_FordVehTrlrEnaReqRaw_Val: accessed-variable=FordVehTrlrEnaReqRaw.Val
            REC_FordVehTrlrHitchAgRateRaw_Val: accessed-variable=FordVehTrlrHitchAgRateRaw.Val
            REC_FordVehTrlrHitchAgVld_Logl: accessed-variable=FordVehTrlrHitchAgVld.Logl
            REC_FordVehTrlrHitchRateVld_Logl: accessed-variable=FordVehTrlrHitchRateVld.Logl
            REC_FordVehTrlrHitchYawAgRaw_Val: accessed-variable=FordVehTrlrHitchYawAgRaw.Val
            REC_FordVehTrlrHitchYawSts_Val: accessed-variable=FordVehTrlrHitchYawSts.Val
            REC_FordVehTrlrIdnTypRaw_Val: accessed-variable=FordVehTrlrIdnTypRaw.Val
            REC_FordVehTrlrLampCnctnStsRaw_Val: accessed-variable=FordVehTrlrLampCnctnStsRaw.Val
            REC_FordVehTrlrRvsCnclReqRaw_Val: accessed-variable=FordVehTrlrRvsCnclReqRaw.Val
            REC_FordVehTrlrRvsEnaRaw_Val: accessed-variable=FordVehTrlrRvsEnaRaw.Val
            REC_FordVehTrlrRvsMsgTxtReqRaw_Val: accessed-variable=FordVehTrlrRvsMsgTxtReqRaw.Val
            REC_FordVehTrlrTarVld_Logl: accessed-variable=FordVehTrlrTarVld.Logl
            REC_FordVehTrlrYawRateQlyFac_Val: accessed-variable=FordVehTrlrYawRateQlyFac.Val
            REC_FordVehTrlrYawRateRaw_Val: accessed-variable=FordVehTrlrYawRateRaw.Val
            REC_FordVehTrsmDesGearRaw_Val: accessed-variable=FordVehTrsmDesGearRaw.Val
            REC_FordVehTurnSigSwtStsRaw_Val: accessed-variable=FordVehTurnSigSwtStsRaw.Val
            REC_FordVehTurnSigVld_Logl: accessed-variable=FordVehTurnSigVld.Logl
            REC_FordVehVertACmpdRaw_Val: accessed-variable=FordVehVertACmpdRaw.Val
            REC_FordVehYawRateCmpdRaw_Val: accessed-variable=FordVehYawRateCmpdRaw.Val
            REC_FordVehYawRateRaw_Ford_VehYaw_W_Actl: accessed-variable=FordVehYawRateRaw.Ford_VehYaw_W_Actl
            REC_FordVehYawRateRawVld_Logl: accessed-variable=FordVehYawRateRawVld.Logl
            REC_FordVehYawRateVld_Logl: accessed-variable=FordVehYawRateVld.Logl
            REC_FordVehYawStabyRaw_Val: accessed-variable=FordVehYawStabyRaw.Val
            REC_FordVehYawStabyVld_Logl: accessed-variable=FordVehYawStabyVld.Logl
            REC_FordYawRateSnsrIdHi_Val: accessed-variable=FordYawRateSnsrIdHi.Val
            REC_FordYawRateSnsrIdLo_Val: accessed-variable=FordYawRateSnsrIdLo.Val
            REC_HwVel_Val: accessed-variable=HwVel.Val
            REC_IntAgCtrlSt_Val: accessed-variable=IntAgCtrlSt.Val
            REC_RackToPinionRat_Val: accessed-variable=RackToPinionRat.Val
            REC_SelnDrvgModSteerModReq_Val: accessed-variable=SelnDrvgModSteerModReq.Val
            REC_SemiAutParlParkAgCtrlSts1_Val: accessed-variable=SemiAutParlParkAgCtrlSts1.Val
            REC_SemiAutParlParkAgCtrlSts{2..5}_Logl: accessed-variable=SemiAutParlParkAgCtrlSts{2..5}.Logl
            REC_TrlrBackupAssiEnaVld_Logl: accessed-variable=TrlrBackupAssiEnaVld.Logl
            REC_TrlrBackupAssiRvsVld_Logl: accessed-variable=TrlrBackupAssiRvsVld.Logl
            REC_TrlrBackupAssiYawRateVld_Logl: accessed-variable=TrlrBackupAssiYawRateVld.Logl
            REC_VehSpd_Val: accessed-variable=VehSpd.Val
            REC_VehSpdVld_Logl: accessed-variable=VehSpdVld.Logl
            REC_VehSteerRat_Val: accessed-variable=VehSteerRat.Val
            REC_VehWhlBas_Val: accessed-variable=VehWhlBas.Val
            REC_VertAVld_Logl: accessed-variable=VertAVld.Logl
  swc implementation CDD_FordBlaBoxIfCmn_Implementation: behavior=CDD_FordBlaBoxIfCmn_InternalBehavior
    code-descriptors:
      code Default: artifact-descriptors=autosar-engineering-object={short-label=Default, category=SWSRC}
